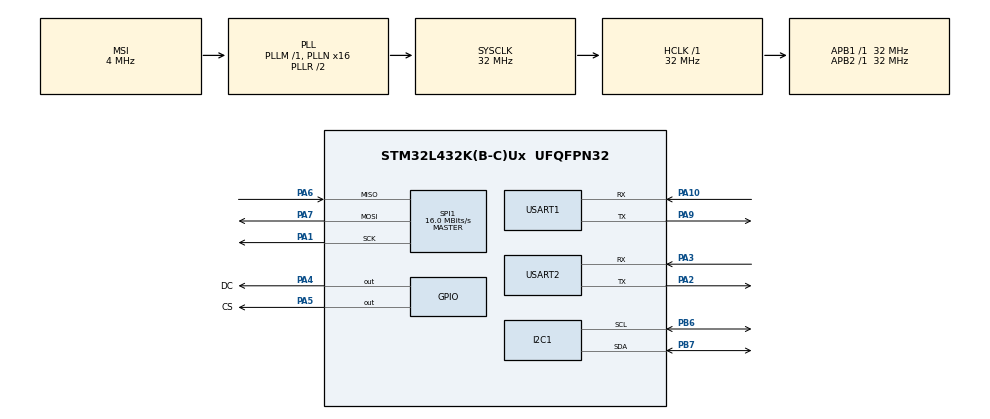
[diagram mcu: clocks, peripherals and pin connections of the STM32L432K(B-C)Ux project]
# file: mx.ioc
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I2C1.Timing=0x00B07CB4
Mcu.Family=STM32L4
Mcu.Name=STM32L432K(B-C)Ux
Mcu.Package=UFQFPN32
NVIC.PriorityGroup=NVIC_PRIORITYGROUP_4
NVIC.TIM2_IRQn=true\:15\:0\:false\:false\:true\:false\:true\:true
NVIC.TimeBase=TIM2_IRQn
NVIC.TimeBaseIP=TIM2
NVIC.USART1_IRQn=true\:5\:0\:true\:false\:true\:true\:true\:true
NVIC.USART2_IRQn=true\:5\:0\:true\:false\:true\:true\:true\:true
PA0.GPIO_Label=MCO [High speed clock in]
PA0.Mode=HSE-External-Clock-Source-for-LittleOrca
PA0.Signal=RCC_CK_IN
PA1.Mode=Full_Duplex_Master
PA1.Signal=SPI1_SCK
PA10.Mode=Asynchronous
PA10.Signal=USART1_RX
PA13\ (JTMS-SWDIO).GPIO_Label=SWDIO
PA13\ (JTMS-SWDIO).Mode=Serial_Wire
PA13\ (JTMS-SWDIO).Signal=SYS_JTMS-SWDIO
PA14\ (JTCK-SWCLK).GPIO_Label=SWCLK
PA14\ (JTCK-SWCLK).Mode=Serial_Wire
PA14\ (JTCK-SWCLK).Signal=SYS_JTCK-SWCLK
PA2.Mode=Asynchronous
PA2.Signal=USART2_TX
PA3.Mode=Asynchronous
PA3.Signal=USART2_RX
PA4.GPIO_Label=DC
PA4.Signal=GPIO_Output
PA5.GPIO_Label=CS
PA5.Signal=GPIO_Output
PA6.Mode=Full_Duplex_Master
PA6.Signal=SPI1_MISO
PA7.Mode=Full_Duplex_Master
PA7.Signal=SPI1_MOSI
PA9.Mode=Asynchronous
PA9.Signal=USART1_TX
PB6.GPIO_Pu=GPIO_PULLUP
PB6.Mode=I2C
PB6.Signal=I2C1_SCL
PB7.GPIO_Pu=GPIO_PULLUP
PB7.Mode=I2C
PB7.Signal=I2C1_SDA
PC14-OSC32_IN\ (PC14).Mode=LSE-External-Oscillator
PC14-OSC32_IN\ (PC14).Signal=RCC_OSC32_IN
PC15-OSC32_OUT\ (PC15).Mode=LSE-External-Oscillator
PC15-OSC32_OUT\ (PC15).Signal=RCC_OSC32_OUT
ProjectManager.HeapSize=0x200
ProjectManager.StackSize=0x400
ProjectManager.TargetToolchain=Makefile
RCC.AHBFreq_Value=32000000
RCC.APB1Freq_Value=32000000
RCC.APB1TimFreq_Value=32000000
RCC.APB2Freq_Value=32000000
RCC.APB2TimFreq_Value=32000000
RCC.CortexFreq_Value=32000000
RCC.HCLKFreq_Value=32000000
RCC.HSE_VALUE=8000000
RCC.HSI16_VALUE=16000000
RCC.HSI48_VALUE=48000000
RCC.HSI_VALUE=16000000
RCC.MSI_VALUE=4000000
RCC.PLLMUL=RCC_PLLMUL_4
RCC.PLLN=16
RCC.SYSCLKFreq_VALUE=32000000
RCC.SYSCLKSource=RCC_SYSCLKSOURCE_PLLCLK
RCC.VCOOutputFreq_Value=64000000
SPI1.CalculateBaudRate=16.0 MBits/s
SPI1.DataSize=SPI_DATASIZE_8BIT
SPI1.Direction=SPI_DIRECTION_2LINES
SPI1.Mode=SPI_MODE_MASTER
SPI1.VirtualType=VM_MASTER
USART1.VirtualMode-Asynchronous=VM_ASYNC
USART2.VirtualMode-Asynchronous=VM_ASYNC
VP_SYS_VS_tim2.Mode=TIM2
board=NUCLEO-L432KC

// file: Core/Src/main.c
/* USER CODE BEGIN Header */
/**
  ******************************************************************************
  * @file           : main.c
  * @brief          : Main program body
  ******************************************************************************
  * @attention
  *
  * Copyright (c) 2026 STMicroelectronics.
  * All rights reserved.
  *
  * This software is licensed under terms that can be found in the LICENSE file
  * in the root directory of this software component.
  * If no LICENSE file comes with this software, it is provided AS-IS.
  *
  ******************************************************************************
  */
/* USER CODE END Header */
#include "main.h"
#include "i2c.h"
#include "spi.h"
#include "usart.h"
#include "gpio.h"

/* USER CODE BEGIN Includes */
#include "stdio.h"
#include "ili9341.h"

#include "FreeRTOS.h"
#include "queue.h"
#include "task.h"
#include <stdio.h>
#include <stdlib.h>
#include <string.h>
/* USER CODE END Includes */

/* USER CODE BEGIN PD */
#define AMG8833_ADDR (0x69 << 1)
/* USER CODE END PD */

/* USER CODE BEGIN PV */

QueueHandle_t uart_queue;

volatile uint8_t rx_byte;

// states
volatile uint8_t auto_mode = 0;
volatile uint8_t thermal_mode = 0;
volatile uint8_t shoot_enabled = 0;

volatile uint16_t aim_value = 1650;

volatile uint16_t motor1_speed = 600;
volatile uint16_t motor2_speed = 600;

const uint16_t image2[] = {
0x07FF,0x07FF,0x07FF,0x07FF,0x07FF,0x07FF,0x07FF,0x07FF,0x07FF,0x07FF,0x07FF,0x07FF,0x07FF,0x07FF,0x07FF,0x07FF,0x07FF,0x07FF,0x07FF,0x07FF,0x07FF,0x07FF,0x07FF,0x07FF,0x07FF,0x07FF,0x07FF,0x07FF,0x07FF,0x07FF,0x07FF,0x07FF,0x07FF,0x07FF,0x07FF,0x07FF,0x07FF,0x0c,0x00,0x00,0x00,0x00,0x00,0x00,0x00,0x00,0x00,0x00,0x11,0x07FF,0x07FF,0x07FF,0x07FF,0x07FF,0x07FF,0x07FF,0x07FF,0x07FF,0x07FF,0x07FF,0x07FF,0x07FF,0x07FF,0x07FF,0x07FF
,0x07FF,0x07FF,0x07FF,0x07FF,0x07FF,0x07FF,0x07FF,0x07FF,0x07FF,0x07FF,0x07FF,0x07FF,0x07FF,0x07FF,0x07FF,0x07FF,0x07FF,0x07FF,0x07FF,0x07FF,0x07FF,0x07FF,0x07FF,0x07FF,0x07FF,0x07FF,0x07FF,0x07FF,0x0c,0x04,0x04,0x04,0x04,0x08,0x07FF,0x07FF,0x0c,0x04,0x00,0xb4,0x24,0x00,0x00,0x00,0x00,0x00,0x24,0xb4,0x04,0x0c,0x07FF,0x07FF,0x04,0x04,0x0c,0x07FF,0x07FF,0x07FF,0x07FF,0x07FF,0x07FF,0x07FF,0x07FF,0x07FF,0x07FF
,0x07FF,0x07FF,0x07FF,0x07FF,0x07FF,0x07FF,0x07FF,0x07FF,0x07FF,0x07FF,0x07FF,0x07FF,0x07FF,0x07FF,0x07FF,0x07FF,0x07FF,0x07FF,0x07FF,0x07FF,0x07FF,0x07FF,0x07FF,0x07FF,0x07FF,0x07FF,0x07FF,0x07FF,0x0c,0x00,0x6c,0x6c,0x24,0x00,0x0c,0x0c,0x04,0x20,0x6c,0x90,0x24,0x00,0x00,0x00,0x00,0x24,0x90,0xfc,0x00,0x04,0x0c,0x0c,0x00,0x00,0x08,0x07FF,0x07FF,0x07FF,0x07FF,0x07FF,0x07FF,0x07FF,0x07FF,0x07FF,0x07FF
,0x07FF,0x07FF,0x07FF,0x07FF,0x07FF,0x07FF,0x07FF,0x07FF,0x07FF,0x07FF,0x07FF,0x07FF,0x07FF,0x07FF,0x07FF,0x07FF,0x07FF,0x07FF,0x07FF,0x07FF,0x07FF,0x07FF,0x07FF,0x07FF,0x07FF,0x07FF,0x07FF,0x07FF,0x0c,0x00,0xd8,0xfc,0x90,0x24,0x24,0x24,0x00,0x44,0xd8,0x24,0x24,0x24,0x24,0x24,0x24,0x6c,0xd8,0xd8,0x24,0x00,0x00,0x00,0x24,0x00,0x08,0x07FF,0x07FF,0x07FF,0x07FF,0x07FF,0x07FF,0x07FF,0x07FF,0x07FF,0x07FF
,0x07FF,0x07FF,0x07FF,0x07FF,0x07FF,0x07FF,0x07FF,0x07FF,0x07FF,0x07FF,0x07FF,0x07FF,0x07FF,0x07FF,0x07FF,0x07FF,0x07FF,0x07FF,0x07FF,0x07FF,0x07FF,0x07FF,0x07FF,0x07FF,0x07FF,0x07FF,0x07FF,0x07FF,0x0c,0x00,0x00,0xd8,0xfc,0xfc,0xfc,0xfc,0x6c,0x00,0x00,0xff,0xff,0xff,0xff,0xff,0xff,0x6d,0x00,0x00,0xf8,0x6c,0x00,0x00,0xfc,0x48,0x08,0x07FF,0x07FF,0x07FF,0x07FF,0x07FF,0x07FF,0x07FF,0x07FF,0x07FF,0x07FF
,0x07FF,0x07FF,0x07FF,0x07FF,0x07FF,0x07FF,0x07FF,0x07FF,0x07FF,0x07FF,0x07FF,0x07FF,0x07FF,0x07FF,0x07FF,0x07FF,0x07FF,0x07FF,0x07FF,0x07FF,0x07FF,0x07FF,0x07FF,0x07FF,0x07FF,0x07FF,0x07FF,0x07FF,0x07FF,0x10,0x00,0x00,0x90,0xfc,0xfc,0x24,0x92,0xdb,0xdb,0xff,0xff,0xff,0xff,0xff,0xff,0xff,0xdb,0xdb,0x24,0x90,0xd8,0xd8,0x24,0x00,0x08,0x07FF,0x07FF,0x07FF,0x07FF,0x07FF,0x07FF,0x07FF,0x07FF,0x07FF,0x07FF
,0x07FF,0x07FF,0x07FF,0x07FF,0x07FF,0x07FF,0x07FF,0x07FF,0x07FF,0x07FF,0x07FF,0x07FF,0x07FF,0x07FF,0x07FF,0x07FF,0x07FF,0x07FF,0x07FF,0x07FF,0x07FF,0x07FF,0x07FF,0x07FF,0x07FF,0x07FF,0x07FF,0x07FF,0x07FF,0x07FF,0x0c,0x00,0x24,0x6c,0x6c,0x92,0xdb,0xff,0xff,0x6d,0x6d,0xb6,0xff,0xff,0x92,0x6d,0x92,0xff,0x92,0x6c,0x90,0xfc,0x00,0x08,0x10,0x07FF,0x07FF,0x07FF,0x07FF,0x07FF,0x07FF,0x07FF,0x07FF,0x07FF,0x07FF
,0x07FF,0x07FF,0x07FF,0x07FF,0x07FF,0x07FF,0x07FF,0x07FF,0x07FF,0x07FF,0x07FF,0x07FF,0x07FF,0x07FF,0x07FF,0x07FF,0x07FF,0x07FF,0x07FF,0x07FF,0x07FF,0x07FF,0x07FF,0x07FF,0x07FF,0x07FF,0x07FF,0x07FF,0x07FF,0x07FF,0x07FF,0x08,0x00,0x00,0x00,0xff,0xff,0xff,0xff,0x00,0x00,0x6d,0xff,0xff,0x24,0x00,0x24,0xff,0xff,0x6d,0x24,0xb4,0x00,0x0c,0x07FF,0x07FF,0x07FF,0x07FF,0x07FF,0x07FF,0x07FF,0x07FF,0x07FF,0x07FF,0x07FF
,0x07FF,0x07FF,0x07FF,0x07FF,0x07FF,0x07FF,0x07FF,0x07FF,0x07FF,0x07FF,0x07FF,0x07FF,0x07FF,0x07FF,0x07FF,0x07FF,0x07FF,0x07FF,0x07FF,0x07FF,0x07FF,0x07FF,0x07FF,0x07FF,0x07FF,0x07FF,0x07FF,0x07FF,0x07FF,0x07FF,0x07FF,0x07FF,0x08,0x00,0x00,0xff,0xff,0xff,0xff,0x00,0x00,0x6d,0xff,0xff,0x24,0x00,0x24,0xff,0xff,0x6d,0x00,0x00,0x00,0x0c,0x07FF,0x07FF,0x07FF,0x07FF,0x07FF,0x07FF,0x07FF,0x07FF,0x07FF,0x07FF,0x07FF
,0x07FF,0x07FF,0x07FF,0x07FF,0x07FF,0x07FF,0x07FF,0x07FF,0x07FF,0x07FF,0x07FF,0x07FF,0x07FF,0x07FF,0x07FF,0x07FF,0x07FF,0x07FF,0x07FF,0x07FF,0x07FF,0x07FF,0x07FF,0x07FF,0x07FF,0x07FF,0x07FF,0x07FF,0x07FF,0x07FF,0x07FF,0x07FF,0x07FF,0x10,0x00,0xff,0xff,0xff,0xff,0xff,0xff,0xff,0xff,0xff,0xff,0xff,0xff,0xff,0xff,0x6d,0x04,0x07FF,0x07FF,0x07FF,0x07FF,0x07FF,0x07FF,0x07FF,0x07FF,0x07FF,0x07FF,0x07FF,0x07FF,0x07FF,0x07FF
,0x07FF,0x07FF,0x07FF,0x07FF,0x07FF,0x07FF,0x07FF,0x07FF,0x07FF,0x07FF,0x07FF,0x07FF,0x07FF,0x07FF,0x07FF,0x07FF,0x07FF,0x07FF,0x07FF,0x07FF,0x07FF,0x07FF,0x07FF,0x07FF,0x07FF,0x07FF,0x07FF,0x07FF,0x07FF,0x07FF,0x07FF,0x07FF,0x07FF,0x10,0x00,0xff,0xff,0xff,0xff,0xff,0xff,0xff,0xff,0xff,0xff,0xff,0xff,0xff,0xff,0x6d,0x04,0x07FF,0x07FF,0x07FF,0x07FF,0x07FF,0x07FF,0x07FF,0x07FF,0x07FF,0x07FF,0x07FF,0x07FF,0x07FF,0x07FF
,0x07FF,0x07FF,0x07FF,0x07FF,0x07FF,0x07FF,0x07FF,0x07FF,0x07FF,0x07FF,0x07FF,0x07FF,0x07FF,0x07FF,0x07FF,0x07FF,0x07FF,0x07FF,0x07FF,0x07FF,0x07FF,0x07FF,0x07FF,0x07FF,0x07FF,0x07FF,0x07FF,0x07FF,0x07FF,0x07FF,0x07FF,0x07FF,0x07FF,0x10,0x00,0xff,0xff,0xdb,0x92,0xff,0xff,0xff,0xff,0xff,0xff,0xdb,0xb6,0xff,0xff,0x6d,0x04,0x07FF,0x07FF,0x07FF,0x07FF,0x07FF,0x07FF,0x07FF,0x07FF,0x07FF,0x07FF,0x07FF,0x07FF,0x07FF,0x07FF
,0x07FF,0x07FF,0x07FF,0x07FF,0x07FF,0x07FF,0x07FF,0x07FF,0x07FF,0x07FF,0x07FF,0x07FF,0x07FF,0x07FF,0x07FF,0x07FF,0x07FF,0x07FF,0x07FF,0x07FF,0x07FF,0x07FF,0x07FF,0x07FF,0x07FF,0x07FF,0x07FF,0x07FF,0x07FF,0x07FF,0x07FF,0x07FF,0x07FF,0x10,0x00,0xff,0xff,0xb6,0x24,0xdb,0xff,0xff,0xff,0xff,0xff,0x6d,0x49,0xff,0xff,0x6d,0x04,0x07FF,0x07FF,0x07FF,0x07FF,0x07FF,0x07FF,0x07FF,0x07FF,0x07FF,0x07FF,0x07FF,0x07FF,0x07FF,0x07FF
,0x07FF,0x07FF,0x07FF,0x07FF,0x07FF,0x07FF,0x07FF,0x07FF,0x07FF,0x07FF,0x07FF,0x07FF,0x07FF,0x07FF,0x07FF,0x07FF,0x07FF,0x07FF,0x07FF,0x07FF,0x07FF,0x07FF,0x07FF,0x07FF,0x07FF,0x07FF,0x07FF,0x07FF,0x07FF,0x07FF,0x07FF,0x07FF,0x07FF,0x10,0x00,0xff,0xff,0xff,0xff,0x00,0xb6,0xff,0xff,0xff,0x24,0x6d,0xff,0xff,0xff,0x6d,0x04,0x07FF,0x07FF,0x07FF,0x07FF,0x07FF,0x07FF,0x07FF,0x07FF,0x07FF,0x07FF,0x07FF,0x07FF,0x07FF,0x07FF
,0x07FF,0x07FF,0x07FF,0x07FF,0x07FF,0x07FF,0x07FF,0x07FF,0x07FF,0x07FF,0x07FF,0x07FF,0x07FF,0x07FF,0x07FF,0x07FF,0x07FF,0x07FF,0x07FF,0x07FF,0x07FF,0x07FF,0x07FF,0x07FF,0x07FF,0x07FF,0x07FF,0x07FF,0x07FF,0x07FF,0x07FF,0x07FF,0x07FF,0x07FF,0x11,0x24,0xb6,0xff,0xff,0xdb,0x49,0x24,0x24,0x24,0xb6,0xff,0xff,0xff,0x24,0x2c,0x11,0x07FF,0x07FF,0x07FF,0x07FF,0x07FF,0x07FF,0x07FF,0x07FF,0x07FF,0x07FF,0x07FF,0x07FF,0x07FF,0x07FF
,0x07FF,0x07FF,0x07FF,0x07FF,0x07FF,0x07FF,0x07FF,0x07FF,0x07FF,0x07FF,0x07FF,0x07FF,0x07FF,0x07FF,0x07FF,0x07FF,0x07FF,0x07FF,0x07FF,0x07FF,0x07FF,0x07FF,0x07FF,0x07FF,0x07FF,0x07FF,0x07FF,0x07FF,0x07FF,0x07FF,0x07FF,0x07FF,0x07FF,0x07FF,0x07FF,0x0c,0x4d,0x6d,0x6d,0xff,0xb6,0x92,0x92,0x92,0xff,0xb6,0x6d,0x6d,0x0c,0x10,0x07FF,0x07FF,0x07FF,0x07FF,0x07FF,0x07FF,0x07FF,0x07FF,0x07FF,0x07FF,0x07FF,0x07FF,0x07FF,0x07FF,0x07FF
,0x07FF,0x07FF,0x07FF,0x07FF,0x07FF,0x07FF,0x07FF,0x07FF,0x07FF,0x07FF,0x07FF,0x07FF,0x07FF,0x07FF,0x07FF,0x07FF,0x07FF,0x07FF,0x07FF,0x07FF,0x07FF,0x07FF,0x07FF,0x07FF,0x07FF,0x07FF,0x07FF,0x07FF,0x07FF,0x07FF,0x07FF,0x07FF,0x07FF,0x07FF,0x07FF,0x07FF,0x0c,0x04,0x04,0xb6,0xb6,0xb6,0xb6,0xb6,0xb6,0x4d,0x04,0x04,0x15,0x07FF,0x07FF,0x07FF,0x07FF,0x07FF,0x07FF,0x07FF,0x07FF,0x07FF,0x07FF,0x07FF,0x07FF,0x07FF,0x07FF,0x07FF,0x07FF
,0x07FF,0x07FF,0x07FF,0x07FF,0x07FF,0x07FF,0x07FF,0x07FF,0x07FF,0x07FF,0x07FF,0x07FF,0x07FF,0x07FF,0x07FF,0x07FF,0x07FF,0x07FF,0x07FF,0x07FF,0x07FF,0x07FF,0x07FF,0x07FF,0x07FF,0x07FF,0x07FF,0x07FF,0x07FF,0x07FF,0x07FF,0x07FF,0x07FF,0x07FF,0x07FF,0x07FF,0x07FF,0x07FF,0x07FF,0x00,0x00,0x00,0x00,0x00,0x00,0x08,0x07FF,0x07FF,0x07FF,0x07FF,0x07FF,0x07FF,0x07FF,0x07FF,0x07FF,0x07FF,0x07FF,0x07FF,0x07FF,0x07FF,0x07FF,0x07FF,0x07FF,0x07FF,0x07FF
,0x07FF,0x07FF,0x07FF,0x07FF,0x07FF,0x07FF,0x07FF,0x07FF,0x07FF,0x07FF,0x07FF,0x07FF,0x07FF,0x07FF,0x07FF,0x07FF,0x07FF,0x07FF,0x07FF,0x07FF,0x07FF,0x07FF,0x07FF,0x07FF,0x07FF,0x07FF,0x07FF,0x07FF,0x07FF,0x07FF,0x07FF,0x07FF,0x07FF,0x07FF,0x07FF,0x07FF,0x07FF,0x07FF,0x07FF,0x00,0x45,0x60,0x60,0x60,0x00,0x08,0x07FF,0x07FF,0x07FF,0x07FF,0x07FF,0x07FF,0x07FF,0x07FF,0x07FF,0x07FF,0x07FF,0x07FF,0x07FF,0x07FF,0x07FF,0x07FF,0x07FF,0x07FF,0x07FF
,0x07FF,0x07FF,0x07FF,0x07FF,0x07FF,0x07FF,0x07FF,0x07FF,0x07FF,0x07FF,0x07FF,0x07FF,0x07FF,0x07FF,0x07FF,0x07FF,0x07FF,0x07FF,0x07FF,0x07FF,0x07FF,0x07FF,0x07FF,0x07FF,0x07FF,0x07FF,0x07FF,0x07FF,0x07FF,0x07FF,0x07FF,0x07FF,0x07FF,0x07FF,0x07FF,0x07FF,0x07FF,0x07FF,0x07FF,0x00,0x45,0x60,0x60,0x60,0x00,0x08,0x07FF,0x07FF,0x07FF,0x07FF,0x07FF,0x07FF,0x07FF,0x07FF,0x07FF,0x07FF,0x07FF,0x07FF,0x07FF,0x07FF,0x07FF,0x07FF,0x07FF,0x07FF,0x07FF
,0x07FF,0x07FF,0x07FF,0x07FF,0x07FF,0x07FF,0x07FF,0x07FF,0x07FF,0x07FF,0x07FF,0x07FF,0x07FF,0x07FF,0x07FF,0x07FF,0x07FF,0x07FF,0x07FF,0x07FF,0x07FF,0x07FF,0x07FF,0x07FF,0x07FF,0x07FF,0x07FF,0x07FF,0x07FF,0x07FF,0x07FF,0x07FF,0x07FF,0x07FF,0x07FF,0x07FF,0x07FF,0x07FF,0x07FF,0x00,0x45,0x60,0x60,0x60,0x00,0x08,0x07FF,0x07FF,0x07FF,0x07FF,0x07FF,0x07FF,0x07FF,0x07FF,0x07FF,0x07FF,0x07FF,0x07FF,0x07FF,0x07FF,0x07FF,0x07FF,0x07FF,0x07FF,0x07FF
,0x07FF,0x07FF,0x07FF,0x07FF,0x07FF,0x07FF,0x07FF,0x07FF,0x07FF,0x07FF,0x07FF,0x07FF,0x07FF,0x07FF,0x07FF,0x07FF,0x07FF,0x07FF,0x07FF,0x07FF,0x07FF,0x07FF,0x07FF,0x07FF,0x07FF,0x07FF,0x07FF,0x07FF,0x07FF,0x11,0x11,0x11,0x11,0x11,0x11,0x11,0x11,0x11,0x11,0x00,0x45,0x60,0x60,0x60,0x00,0x08,0x11,0x11,0x11,0x11,0x11,0x11,0x11,0x11,0x11,0x11,0x07FF,0x07FF,0x07FF,0x07FF,0x07FF,0x07FF,0x07FF,0x07FF,0x07FF
,0x07FF,0x07FF,0x07FF,0x07FF,0x07FF,0x07FF,0x07FF,0x07FF,0x07FF,0x07FF,0x07FF,0x07FF,0x07FF,0x07FF,0x07FF,0x07FF,0x07FF,0x07FF,0x07FF,0x07FF,0x07FF,0x07FF,0x07FF,0x07FF,0x07FF,0x07FF,0x07FF,0x07FF,0x0c,0x00,0x00,0x00,0x00,0x00,0x00,0x00,0x00,0x00,0x00,0x00,0x45,0x60,0x60,0x60,0x00,0x00,0x00,0x00,0x00,0x00,0x00,0x00,0x00,0x00,0x00,0x00,0x07FF,0x07FF,0x07FF,0x07FF,0x07FF,0x07FF,0x07FF,0x07FF,0x07FF
,0x07FF,0x07FF,0x07FF,0x07FF,0x07FF,0x07FF,0x07FF,0x07FF,0x07FF,0x07FF,0x07FF,0x07FF,0x07FF,0x07FF,0x07FF,0x07FF,0x07FF,0x07FF,0x07FF,0x07FF,0x07FF,0x07FF,0x07FF,0x07FF,0x07FF,0x07FF,0x07FF,0x08,0x20,0x46,0x46,0x46,0x46,0x46,0x46,0x46,0x46,0x46,0x46,0x46,0x60,0x60,0x60,0x60,0x60,0x46,0x46,0x46,0x46,0x46,0x46,0x46,0x46,0x46,0x46,0x45,0x00,0x10,0x07FF,0x07FF,0x07FF,0x07FF,0x07FF,0x07FF,0x07FF
,0x07FF,0x07FF,0x07FF,0x07FF,0x07FF,0x07FF,0x07FF,0x07FF,0x07FF,0x07FF,0x07FF,0x07FF,0x07FF,0x07FF,0x07FF,0x07FF,0x07FF,0x07FF,0x07FF,0x07FF,0x07FF,0x07FF,0x07FF,0x07FF,0x07FF,0x07FF,0x08,0x25,0x45,0x60,0x60,0x60,0x60,0x60,0x60,0x60,0x60,0x60,0x60,0x60,0x60,0x60,0x60,0x60,0x60,0x60,0x60,0x60,0x60,0x60,0x60,0x60,0x60,0x60,0x60,0x60,0x21,0x08,0x0c,0x07FF,0x07FF,0x07FF,0x07FF,0x07FF,0x07FF
,0x07FF,0x07FF,0x07FF,0x07FF,0x07FF,0x07FF,0x07FF,0x07FF,0x07FF,0x07FF,0x07FF,0x07FF,0x07FF,0x07FF,0x07FF,0x07FF,0x07FF,0x07FF,0x07FF,0x07FF,0x07FF,0x07FF,0x07FF,0x07FF,0x15,0x0c,0x00,0x45,0x60,0x60,0x60,0x60,0x60,0x60,0x60,0x60,0x60,0x60,0x60,0x60,0x60,0x60,0x60,0x60,0x60,0x60,0x60,0x60,0x60,0x60,0x60,0x60,0x60,0x60,0x60,0x60,0x60,0x21,0x08,0x10,0x07FF,0x07FF,0x07FF,0x07FF,0x07FF
,0x07FF,0x07FF,0x07FF,0x07FF,0x07FF,0x07FF,0x07FF,0x07FF,0x07FF,0x07FF,0x07FF,0x07FF,0x07FF,0x07FF,0x07FF,0x07FF,0x07FF,0x07FF,0x07FF,0x07FF,0x07FF,0x07FF,0x07FF,0x07FF,0x0c,0x00,0x60,0x60,0x60,0x60,0x60,0x60,0x60,0x60,0x60,0x60,0x60,0x60,0x60,0x60,0x60,0x60,0x60,0x60,0x60,0x60,0x60,0x60,0x60,0x60,0x60,0x60,0x60,0x60,0x60,0x60,0x60,0x60,0x21,0x04,0x07FF,0x07FF,0x07FF,0x07FF,0x07FF
,0x07FF,0x07FF,0x07FF,0x07FF,0x07FF,0x07FF,0x07FF,0x07FF,0x07FF,0x07FF,0x07FF,0x07FF,0x07FF,0x07FF,0x07FF,0x07FF,0x07FF,0x07FF,0x07FF,0x07FF,0x07FF,0x07FF,0x07FF,0x08,0x20,0x60,0x60,0x60,0x60,0x60,0x60,0x60,0x60,0x60,0x60,0x60,0x60,0x60,0x60,0x60,0x60,0x60,0x60,0x60,0x60,0x60,0x60,0x60,0x60,0x60,0x60,0x60,0x60,0x60,0x60,0x60,0x60,0x60,0x60,0x45,0x00,0x11,0x07FF,0x07FF,0x07FF
,0x07FF,0x07FF,0x07FF,0x07FF,0x07FF,0x07FF,0x07FF,0x07FF,0x07FF,0x07FF,0x07FF,0x07FF,0x07FF,0x07FF,0x07FF,0x07FF,0x07FF,0x07FF,0x07FF,0x07FF,0x07FF,0x07FF,0x04,0x25,0x45,0x60,0x60,0x60,0x60,0x60,0x60,0x60,0x60,0x60,0x60,0x60,0x60,0x60,0x60,0x60,0x60,0x60,0x60,0x60,0x60,0x60,0x60,0x60,0x60,0x60,0x60,0x60,0x60,0x60,0x60,0x60,0x60,0x60,0x60,0x45,0x00,0x11,0x07FF,0x07FF,0x07FF
,0x07FF,0x07FF,0x07FF,0x07FF,0x07FF,0x07FF,0x07FF,0x07FF,0x07FF,0x07FF,0x07FF,0x07FF,0x07FF,0x07FF,0x07FF,0x07FF,0x07FF,0x07FF,0x07FF,0x07FF,0x07FF,0x07FF,0x00,0x20,0x45,0x60,0x60,0x60,0x60,0x60,0x60,0x45,0x21,0x45,0x60,0x60,0x60,0x60,0x60,0x60,0x60,0x60,0x60,0x60,0x60,0x60,0x60,0x60,0x60,0x60,0x60,0x21,0x21,0x60,0x60,0x60,0x60,0x60,0x60,0x45,0x00,0x11,0x07FF,0x07FF,0x07FF
,0x07FF,0x07FF,0x07FF,0x07FF,0x07FF,0x07FF,0x07FF,0x07FF,0x07FF,0x07FF,0x07FF,0x07FF,0x07FF,0x07FF,0x07FF,0x07FF,0x07FF,0x07FF,0x07FF,0x07FF,0x07FF,0x11,0x00,0x00,0x25,0x46,0x60,0x60,0x60,0x60,0x46,0x00,0x00,0x00,0x60,0x60,0x60,0x60,0x60,0x60,0x60,0x60,0x60,0x60,0x60,0x60,0x60,0x60,0x60,0x60,0x45,0x00,0x00,0x45,0x60,0x60,0x60,0x60,0x60,0x45,0x00,0x11,0x07FF,0x07FF,0x07FF
,0x07FF,0x07FF,0x07FF,0x07FF,0x07FF,0x07FF,0x07FF,0x07FF,0x07FF,0x07FF,0x07FF,0x07FF,0x07FF,0x07FF,0x07FF,0x07FF,0x07FF,0x07FF,0x07FF,0x07FF,0x10,0x00,0x00,0x92,0xb6,0x00,0x60,0x60,0x60,0x60,0x00,0x10,0x08,0x00,0x60,0x60,0x60,0x60,0x60,0x60,0x60,0x60,0x60,0x60,0x60,0x60,0x60,0x60,0x60,0x60,0x45,0x00,0x00,0x45,0x60,0x60,0x60,0x60,0x60,0x45,0x00,0x11,0x07FF,0x07FF,0x07FF
,0x07FF,0x07FF,0x07FF,0x07FF,0x07FF,0x07FF,0x07FF,0x07FF,0x07FF,0x07FF,0x07FF,0x07FF,0x07FF,0x07FF,0x07FF,0x07FF,0x07FF,0x07FF,0x07FF,0x0c,0x00,0x00,0xdb,0xff,0xff,0xdb,0x00,0x45,0x45,0x00,0x11,0x07FF,0x08,0x00,0x60,0x60,0x60,0x60,0x60,0x60,0x60,0x60,0x60,0x60,0x60,0x60,0x60,0x60,0x60,0x60,0x45,0x00,0x00,0x45,0x60,0x60,0x60,0x60,0x60,0x45,0x00,0x11,0x07FF,0x07FF,0x07FF
,0x07FF,0x07FF,0x07FF,0x07FF,0x07FF,0x07FF,0x07FF,0x07FF,0x07FF,0x07FF,0x07FF,0x07FF,0x07FF,0x07FF,0x07FF,0x07FF,0x07FF,0x07FF,0x0c,0x04,0x00,0x92,0xff,0xff,0xff,0xff,0x00,0x20,0x24,0x0c,0x07FF,0x07FF,0x08,0x00,0x60,0x60,0x60,0x60,0x60,0x60,0x60,0x60,0x60,0x60,0x60,0x60,0x60,0x60,0x60,0x60,0x45,0x00,0x00,0x45,0x60,0x60,0x60,0x60,0x60,0x45,0x00,0x11,0x07FF,0x07FF,0x07FF
,0x07FF,0x07FF,0x07FF,0x07FF,0x07FF,0x07FF,0x07FF,0x07FF,0x07FF,0x07FF,0x07FF,0x07FF,0x07FF,0x07FF,0x07FF,0x07FF,0x07FF,0x0c,0x00,0x24,0x6d,0xff,0xff,0xff,0xff,0xb6,0x00,0x04,0x0c,0x07FF,0x07FF,0x07FF,0x08,0x00,0x60,0x60,0x60,0x60,0x60,0x60,0x60,0x60,0x60,0x60,0x60,0x60,0x60,0x60,0x60,0x60,0x45,0x00,0x00,0x45,0x60,0x60,0x60,0x60,0x60,0x45,0x00,0x11,0x07FF,0x07FF,0x07FF
,0x07FF,0x07FF,0x07FF,0x07FF,0x07FF,0x07FF,0x07FF,0x07FF,0x07FF,0x07FF,0x07FF,0x07FF,0x07FF,0x07FF,0x07FF,0x07FF,0x11,0x00,0x00,0x6d,0xff,0xff,0xff,0xff,0xb6,0x00,0x00,0x0c,0x07FF,0x07FF,0x07FF,0x07FF,0x08,0x00,0x60,0x60,0x60,0x60,0x60,0x60,0x60,0x60,0x60,0x60,0x60,0x60,0x60,0x60,0x60,0x60,0x45,0x00,0x00,0x45,0x60,0x60,0x60,0x60,0x60,0x45,0x00,0x11,0x07FF,0x07FF,0x07FF
,0x07FF,0x07FF,0x07FF,0x11,0x00,0x00,0x00,0x00,0x00,0x11,0x07FF,0x07FF,0x07FF,0x07FF,0x07FF,0x0c,0x00,0x00,0xdb,0xff,0xff,0xff,0xff,0x6d,0x00,0x00,0x07FF,0x07FF,0x07FF,0x07FF,0x07FF,0x07FF,0x08,0x00,0x60,0x60,0x60,0x60,0x60,0x60,0x60,0x60,0x60,0x60,0x60,0x60,0x60,0x60,0x60,0x60,0x45,0x00,0x00,0x45,0x60,0x60,0x60,0x60,0x60,0x45,0x00,0x11,0x07FF,0x07FF,0x07FF
,0x07FF,0x07FF,0x0c,0x04,0xa0,0xa0,0xa0,0xa0,0xa0,0x04,0x0c,0x07FF,0x07FF,0x07FF,0x08,0x00,0x00,0x00,0xdb,0xff,0xff,0xff,0x49,0x00,0x04,0x0c,0x07FF,0x07FF,0x07FF,0x07FF,0x07FF,0x07FF,0x08,0x00,0x60,0x60,0x60,0x60,0x60,0x60,0x60,0x60,0x60,0x60,0x60,0x60,0x60,0x60,0x60,0x60,0x45,0x00,0x00,0x00,0x00,0x00,0x00,0x00,0x00,0x00,0x00,0x11,0x07FF,0x07FF,0x07FF
,0x07FF,0x0c,0x28,0x60,0xe0,0xe0,0xe0,0xe0,0xe0,0x60,0x28,0x0c,0x07FF,0x07FF,0x04,0x00,0x00,0x6d,0xff,0xff,0xff,0x92,0x00,0x04,0x0c,0x07FF,0x07FF,0x07FF,0x07FF,0x07FF,0x07FF,0x07FF,0x08,0x00,0x60,0x60,0x60,0x60,0x60,0x60,0x60,0x60,0x60,0x60,0x60,0x60,0x60,0x60,0x60,0x60,0x45,0x00,0x08,0x08,0x04,0x00,0x6d,0x6d,0x24,0x00,0x08,0x07FF,0x07FF,0x07FF,0x07FF
,0x07FF,0x04,0x40,0xe0,0xe0,0xe0,0xe0,0xe0,0xe0,0xe0,0x40,0x04,0x07FF,0x11,0x04,0x00,0x24,0xff,0xff,0xff,0xb6,0x00,0x00,0x0c,0x07FF,0x07FF,0x07FF,0x07FF,0x07FF,0x07FF,0x07FF,0x07FF,0x08,0x00,0x60,0x60,0x60,0x60,0x60,0x60,0x60,0x60,0x60,0x60,0x60,0x60,0x60,0x60,0x60,0x60,0x45,0x00,0x07FF,0x07FF,0x0c,0x00,0xff,0xff,0x6d,0x04,0x07FF,0x07FF,0x07FF,0x07FF,0x07FF
,0x07FF,0x04,0x40,0xe0,0xe0,0xe0,0xe0,0xe0,0xe0,0xe0,0x40,0x04,0x07FF,0x00,0x00,0x6d,0xff,0xff,0xff,0x6d,0x00,0x00,0x11,0x07FF,0x07FF,0x07FF,0x07FF,0x07FF,0x07FF,0x07FF,0x07FF,0x07FF,0x08,0x00,0x60,0x60,0x60,0x60,0x60,0x60,0x60,0x60,0x60,0x60,0x60,0x60,0x60,0x60,0x60,0x60,0x45,0x00,0x07FF,0x07FF,0x0c,0x00,0xff,0xff,0x6d,0x04,0x07FF,0x07FF,0x07FF,0x07FF,0x07FF
,0x07FF,0x04,0x40,0xe0,0xe0,0xe0,0xe0,0xe0,0xe0,0xe0,0x40,0x00,0x00,0x00,0x92,0xff,0xff,0xff,0x49,0x00,0x00,0x11,0x07FF,0x07FF,0x07FF,0x07FF,0x07FF,0x07FF,0x07FF,0x07FF,0x07FF,0x07FF,0x08,0x00,0x60,0x60,0x60,0x60,0x60,0x60,0x60,0x60,0x60,0x60,0x60,0x60,0x60,0x60,0x60,0x60,0x45,0x00,0x07FF,0x07FF,0x0c,0x00,0xff,0xff,0x6d,0x04,0x07FF,0x07FF,0x07FF,0x07FF,0x07FF
,0x07FF,0x04,0x40,0xe0,0xe0,0xe0,0xe0,0xe0,0xe0,0xe0,0x40,0x00,0x00,0x92,0xdb,0xff,0xff,0x6d,0x00,0x04,0x0c,0x07FF,0x07FF,0x07FF,0x07FF,0x07FF,0x07FF,0x07FF,0x07FF,0x07FF,0x07FF,0x07FF,0x08,0x00,0x60,0x60,0x60,0x60,0x60,0x60,0x60,0x60,0x60,0x60,0x60,0x60,0x60,0x60,0x60,0x60,0x45,0x00,0x07FF,0x07FF,0x0c,0x00,0xff,0xff,0x6d,0x04,0x07FF,0x07FF,0x07FF,0x07FF,0x07FF
,0x07FF,0x08,0x44,0xa0,0xe0,0xe0,0xe0,0xe0,0xe0,0xa0,0x40,0x00,0x00,0xff,0xff,0xff,0xb6,0x00,0x04,0x0c,0x07FF,0x07FF,0x07FF,0x07FF,0x07FF,0x07FF,0x07FF,0x07FF,0x07FF,0x07FF,0x07FF,0x07FF,0x08,0x00,0x60,0x60,0x60,0x60,0x60,0x60,0x60,0x60,0x60,0x60,0x60,0x60,0x60,0x60,0x60,0x60,0x45,0x00,0x07FF,0x07FF,0x0c,0x00,0xff,0xff,0x6d,0x04,0x07FF,0x07FF,0x07FF,0x07FF,0x07FF
,0x07FF,0x07FF,0x0c,0x00,0xe0,0xe0,0xe0,0xe0,0xe0,0x00,0x00,0x00,0x00,0xff,0xff,0x92,0x00,0x00,0x10,0x07FF,0x07FF,0x07FF,0x07FF,0x07FF,0x07FF,0x07FF,0x07FF,0x07FF,0x07FF,0x07FF,0x07FF,0x07FF,0x08,0x00,0x60,0x60,0x60,0x60,0x60,0x60,0x60,0x60,0x60,0x60,0x60,0x60,0x60,0x60,0x60,0x60,0x45,0x00,0x07FF,0x07FF,0x0c,0x00,0xff,0xff,0x6d,0x04,0x07FF,0x07FF,0x07FF,0x07FF,0x07FF
,0x07FF,0x07FF,0x07FF,0x11,0x00,0x00,0x00,0x00,0x00,0x00,0x00,0x00,0x00,0xff,0x49,0x00,0x00,0x07FF,0x07FF,0x07FF,0x07FF,0x07FF,0x07FF,0x07FF,0x07FF,0x07FF,0x07FF,0x07FF,0x07FF,0x07FF,0x07FF,0x07FF,0x08,0x00,0x60,0x60,0x60,0x60,0x60,0x60,0x60,0x60,0x60,0x60,0x60,0x60,0x60,0x60,0x60,0x60,0x45,0x00,0x07FF,0x07FF,0x0c,0x00,0xff,0xff,0x6d,0x04,0x07FF,0x07FF,0x07FF,0x07FF,0x07FF
,0x07FF,0x07FF,0x07FF,0x07FF,0x0c,0x0c,0x0c,0x0c,0x0c,0x0c,0x04,0x00,0x00,0x49,0x00,0x04,0x10,0x07FF,0x07FF,0x07FF,0x07FF,0x07FF,0x07FF,0x07FF,0x07FF,0x07FF,0x07FF,0x07FF,0x07FF,0x07FF,0x07FF,0x07FF,0x08,0x00,0x60,0x60,0x60,0x60,0x60,0x60,0x60,0x60,0x60,0x60,0x60,0x60,0x60,0x60,0x60,0x60,0x45,0x00,0x07FF,0x07FF,0x0c,0x00,0xff,0xff,0x6d,0x04,0x07FF,0x07FF,0x07FF,0x07FF,0x07FF
,0x07FF,0x07FF,0x07FF,0x07FF,0x07FF,0x07FF,0x07FF,0x07FF,0x07FF,0x07FF,0x0c,0x04,0x00,0x00,0x04,0x0c,0x07FF,0x07FF,0x07FF,0x07FF,0x07FF,0x07FF,0x07FF,0x07FF,0x07FF,0x07FF,0x07FF,0x07FF,0x07FF,0x07FF,0x07FF,0x07FF,0x08,0x00,0x60,0x60,0x60,0x60,0x60,0x60,0x60,0x60,0x60,0x60,0x60,0x60,0x60,0x60,0x60,0x60,0x45,0x00,0x07FF,0x07FF,0x0c,0x00,0xff,0xff,0x6d,0x04,0x07FF,0x07FF,0x07FF,0x07FF,0x07FF
,0x07FF,0x07FF,0x07FF,0x07FF,0x07FF,0x07FF,0x07FF,0x07FF,0x07FF,0x07FF,0x07FF,0x10,0x00,0x00,0x10,0x07FF,0x07FF,0x07FF,0x07FF,0x07FF,0x07FF,0x07FF,0x07FF,0x07FF,0x07FF,0x07FF,0x07FF,0x07FF,0x07FF,0x07FF,0x07FF,0x07FF,0x08,0x00,0x60,0x60,0x60,0x60,0x60,0x60,0x60,0x60,0x60,0x60,0x60,0x60,0x60,0x60,0x60,0x60,0x45,0x00,0x07FF,0x11,0x08,0x00,0xff,0xff,0x6d,0x04,0x07FF,0x07FF,0x07FF,0x07FF,0x07FF
,0x07FF,0x07FF,0x07FF,0x07FF,0x07FF,0x07FF,0x07FF,0x07FF,0x07FF,0x07FF,0x07FF,0x07FF,0x07FF,0x07FF,0x07FF,0x07FF,0x07FF,0x07FF,0x07FF,0x07FF,0x07FF,0x07FF,0x07FF,0x07FF,0x07FF,0x07FF,0x07FF,0x07FF,0x07FF,0x07FF,0x07FF,0x07FF,0x08,0x00,0x60,0x60,0x60,0x60,0x60,0x60,0x60,0x60,0x60,0x60,0x60,0x60,0x60,0x60,0x60,0x60,0x45,0x00,0x07FF,0x04,0x00,0x00,0xff,0xff,0x6d,0x04,0x07FF,0x07FF,0x07FF,0x07FF,0x07FF
,0x07FF,0x07FF,0x07FF,0x07FF,0x07FF,0x07FF,0x07FF,0x07FF,0x07FF,0x07FF,0x07FF,0x07FF,0x07FF,0x07FF,0x07FF,0x07FF,0x07FF,0x07FF,0x07FF,0x07FF,0x07FF,0x07FF,0x07FF,0x07FF,0x07FF,0x07FF,0x07FF,0x07FF,0x07FF,0x07FF,0x07FF,0x07FF,0x08,0x00,0x60,0x60,0x60,0x60,0x60,0x60,0x60,0x60,0x60,0x60,0x60,0x60,0x60,0x60,0x60,0x60,0x45,0x00,0x07FF,0x04,0x49,0xdb,0xff,0x49,0x00,0x04,0x07FF,0x07FF,0x07FF,0x07FF,0x07FF
,0x07FF,0x07FF,0x07FF,0x07FF,0x07FF,0x07FF,0x07FF,0x07FF,0x07FF,0x07FF,0x07FF,0x07FF,0x07FF,0x07FF,0x07FF,0x07FF,0x07FF,0x07FF,0x07FF,0x07FF,0x07FF,0x07FF,0x07FF,0x07FF,0x07FF,0x07FF,0x07FF,0x07FF,0x07FF,0x07FF,0x07FF,0x07FF,0x08,0x00,0x60,0x60,0x60,0x60,0x60,0x60,0x60,0x60,0x60,0x60,0x60,0x60,0x60,0x60,0x60,0x60,0x45,0x00,0x08,0x00,0x6d,0xff,0xff,0x24,0x04,0x0c,0x07FF,0x07FF,0x07FF,0x07FF,0x07FF
,0x07FF,0x07FF,0x07FF,0x07FF,0x07FF,0x07FF,0x07FF,0x07FF,0x07FF,0x07FF,0x07FF,0x07FF,0x07FF,0x07FF,0x07FF,0x07FF,0x07FF,0x07FF,0x07FF,0x07FF,0x07FF,0x07FF,0x07FF,0x07FF,0x07FF,0x07FF,0x07FF,0x07FF,0x07FF,0x07FF,0x07FF,0x07FF,0x08,0x00,0x60,0x60,0x60,0x60,0x60,0x60,0x60,0x60,0x60,0x60,0x60,0x60,0x60,0x60,0x60,0x60,0x45,0x00,0x00,0x24,0x92,0xff,0xb6,0x24,0x08,0x07FF,0x07FF,0x07FF,0x07FF,0x07FF,0x07FF
,0x07FF,0x07FF,0x07FF,0x07FF,0x07FF,0x07FF,0x07FF,0x07FF,0x07FF,0x07FF,0x07FF,0x07FF,0x07FF,0x07FF,0x07FF,0x07FF,0x07FF,0x07FF,0x07FF,0x07FF,0x07FF,0x07FF,0x07FF,0x07FF,0x07FF,0x07FF,0x07FF,0x07FF,0x07FF,0x07FF,0x07FF,0x07FF,0x08,0x00,0x60,0x60,0x60,0x60,0x60,0x60,0x60,0x60,0x60,0x60,0x60,0x60,0x60,0x60,0x60,0x60,0x45,0x00,0x00,0xb6,0xff,0xff,0x00,0x00,0x08,0x07FF,0x07FF,0x07FF,0x07FF,0x07FF,0x07FF
,0x07FF,0x07FF,0x07FF,0x07FF,0x07FF,0x07FF,0x07FF,0x07FF,0x07FF,0x07FF,0x07FF,0x07FF,0x07FF,0x07FF,0x07FF,0x07FF,0x07FF,0x07FF,0x07FF,0x07FF,0x07FF,0x07FF,0x07FF,0x07FF,0x07FF,0x07FF,0x07FF,0x07FF,0x07FF,0x07FF,0x07FF,0x07FF,0x08,0x00,0x00,0x00,0x00,0x00,0x00,0x00,0x00,0x00,0x00,0x00,0x00,0x00,0x00,0x00,0x00,0x00,0x00,0x00,0x00,0xb6,0xff,0xff,0x00,0x10,0x07FF,0x07FF,0x07FF,0x07FF,0x07FF,0x07FF,0x07FF
,0x07FF,0x07FF,0x07FF,0x07FF,0x07FF,0x07FF,0x07FF,0x07FF,0x07FF,0x07FF,0x07FF,0x07FF,0x07FF,0x07FF,0x07FF,0x07FF,0x07FF,0x07FF,0x07FF,0x07FF,0x07FF,0x07FF,0x07FF,0x07FF,0x07FF,0x07FF,0x07FF,0x07FF,0x07FF,0x07FF,0x07FF,0x07FF,0x08,0x00,0x00,0x00,0x00,0x00,0x00,0x00,0x00,0x00,0x00,0x00,0x00,0x00,0x00,0x00,0x00,0x00,0x00,0x00,0xb6,0xff,0xb6,0x49,0x0c,0x07FF,0x07FF,0x07FF,0x07FF,0x07FF,0x07FF,0x07FF,0x07FF
,0x07FF,0x07FF,0x07FF,0x07FF,0x07FF,0x07FF,0x07FF,0x07FF,0x07FF,0x07FF,0x07FF,0x07FF,0x07FF,0x07FF,0x07FF,0x07FF,0x07FF,0x07FF,0x07FF,0x07FF,0x07FF,0x07FF,0x07FF,0x07FF,0x07FF,0x07FF,0x07FF,0x07FF,0x07FF,0x07FF,0x07FF,0x07FF,0x08,0x00,0x00,0x00,0x00,0x00,0x00,0x00,0x00,0x00,0x00,0x00,0x00,0x00,0x00,0x00,0x00,0x00,0x00,0x00,0xff,0xb6,0x49,0x00,0x07FF,0x07FF,0x07FF,0x07FF,0x07FF,0x07FF,0x07FF,0x07FF,0x07FF
,0x07FF,0x07FF,0x07FF,0x07FF,0x07FF,0x07FF,0x07FF,0x07FF,0x07FF,0x07FF,0x07FF,0x07FF,0x07FF,0x07FF,0x07FF,0x07FF,0x07FF,0x07FF,0x07FF,0x07FF,0x07FF,0x07FF,0x07FF,0x07FF,0x07FF,0x07FF,0x07FF,0x07FF,0x07FF,0x07FF,0x07FF,0x07FF,0x08,0x00,0x00,0x00,0x00,0x00,0x00,0x00,0x00,0x00,0x00,0x00,0x00,0x00,0x00,0x00,0x00,0x00,0x00,0x00,0xdb,0x49,0x00,0x04,0x07FF,0x07FF,0x07FF,0x07FF,0x07FF,0x07FF,0x07FF,0x07FF,0x07FF
,0x07FF,0x07FF,0x07FF,0x07FF,0x07FF,0x07FF,0x07FF,0x07FF,0x07FF,0x07FF,0x07FF,0x07FF,0x07FF,0x07FF,0x07FF,0x07FF,0x07FF,0x07FF,0x07FF,0x07FF,0x07FF,0x07FF,0x07FF,0x07FF,0x07FF,0x07FF,0x07FF,0x07FF,0x07FF,0x07FF,0x07FF,0x07FF,0x08,0x00,0x00,0x00,0x00,0x00,0x00,0x00,0x00,0x00,0x00,0x00,0x00,0x00,0x00,0x00,0x00,0x00,0x00,0x00,0x00,0x00,0x08,0x07FF,0x07FF,0x07FF,0x07FF,0x07FF,0x07FF,0x07FF,0x07FF,0x07FF,0x07FF
,0x07FF,0x07FF,0x07FF,0x07FF,0x07FF,0x07FF,0x07FF,0x07FF,0x07FF,0x07FF,0x07FF,0x07FF,0x07FF,0x07FF,0x07FF,0x07FF,0x07FF,0x07FF,0x07FF,0x07FF,0x07FF,0x07FF,0x07FF,0x07FF,0x07FF,0x07FF,0x07FF,0x07FF,0x07FF,0x07FF,0x07FF,0x07FF,0x08,0x00,0x00,0x00,0x00,0x00,0x00,0x00,0x00,0x00,0x00,0x00,0x00,0x00,0x00,0x00,0x00,0x00,0x00,0x00,0x11,0x11,0x15,0x07FF,0x07FF,0x07FF,0x07FF,0x07FF,0x07FF,0x07FF,0x07FF,0x07FF,0x07FF
,0x07FF,0x07FF,0x07FF,0x07FF,0x07FF,0x07FF,0x07FF,0x07FF,0x07FF,0x07FF,0x07FF,0x07FF,0x07FF,0x07FF,0x07FF,0x07FF,0x07FF,0x07FF,0x07FF,0x07FF,0x07FF,0x07FF,0x07FF,0x07FF,0x07FF,0x07FF,0x07FF,0x07FF,0x07FF,0x07FF,0x07FF,0x07FF,0x08,0x00,0x00,0x00,0x00,0x00,0x00,0x00,0x00,0x00,0x00,0x00,0x00,0x00,0x00,0x00,0x00,0x00,0x00,0x00,0x07FF,0x07FF,0x07FF,0x07FF,0x07FF,0x07FF,0x07FF,0x07FF,0x07FF,0x07FF,0x07FF,0x07FF,0x07FF
,0x07FF,0x07FF,0x07FF,0x07FF,0x07FF,0x07FF,0x07FF,0x07FF,0x07FF,0x07FF,0x07FF,0x07FF,0x07FF,0x07FF,0x07FF,0x07FF,0x07FF,0x07FF,0x07FF,0x07FF,0x07FF,0x07FF,0x07FF,0x07FF,0x07FF,0x07FF,0x07FF,0x07FF,0x07FF,0x07FF,0x07FF,0x07FF,0x08,0x00,0x00,0x00,0x00,0x00,0x00,0x00,0x00,0x00,0x00,0x00,0x00,0x00,0x00,0x00,0x00,0x00,0x00,0x00,0x07FF,0x07FF,0x07FF,0x07FF,0x07FF,0x07FF,0x07FF,0x07FF,0x07FF,0x07FF,0x07FF,0x07FF,0x07FF
,0x07FF,0x07FF,0x07FF,0x07FF,0x07FF,0x07FF,0x07FF,0x07FF,0x07FF,0x07FF,0x07FF,0x07FF,0x07FF,0x07FF,0x07FF,0x07FF,0x07FF,0x07FF,0x07FF,0x07FF,0x07FF,0x07FF,0x07FF,0x07FF,0x07FF,0x07FF,0x07FF,0x07FF,0x07FF,0x07FF,0x07FF,0x07FF,0x08,0x00,0x00,0x00,0x00,0x00,0x00,0x00,0x00,0x00,0x00,0x00,0x00,0x00,0x00,0x00,0x00,0x00,0x00,0x00,0x07FF,0x07FF,0x07FF,0x07FF,0x07FF,0x07FF,0x07FF,0x07FF,0x07FF,0x07FF,0x07FF,0x07FF,0x07FF
,0x07FF,0x07FF,0x07FF,0x07FF,0x07FF,0x07FF,0x07FF,0x07FF,0x07FF,0x07FF,0x07FF,0x07FF,0x07FF,0x07FF,0x07FF,0x07FF,0x07FF,0x07FF,0x07FF,0x07FF,0x07FF,0x07FF,0x07FF,0x07FF,0x07FF,0x07FF,0x07FF,0x07FF,0x07FF,0x07FF,0x07FF,0x07FF,0x08,0x00,0x00,0x00,0x00,0x00,0x00,0x00,0x00,0x00,0x00,0x00,0x00,0x00,0x00,0x00,0x00,0x00,0x00,0x00,0x07FF,0x07FF,0x07FF,0x07FF,0x07FF,0x07FF,0x07FF,0x07FF,0x07FF,0x07FF,0x07FF,0x07FF,0x07FF
,0x07FF,0x07FF,0x07FF,0x07FF,0x07FF,0x07FF,0x07FF,0x07FF,0x07FF,0x07FF,0x07FF,0x07FF,0x07FF,0x07FF,0x07FF,0x07FF,0x07FF,0x07FF,0x07FF,0x07FF,0x07FF,0x07FF,0x07FF,0x07FF,0x07FF,0x07FF,0x07FF,0x07FF,0x07FF,0x07FF,0x07FF,0x07FF,0x08,0x00,0x00,0x00,0x00,0x00,0x00,0x00,0x00,0x00,0x00,0x00,0x00,0x00,0x00,0x00,0x00,0x00,0x00,0x00,0x07FF,0x07FF,0x07FF,0x07FF,0x07FF,0x07FF,0x07FF,0x07FF,0x07FF,0x07FF,0x07FF,0x07FF,0x07FF
,0x07FF,0x07FF,0x07FF,0x07FF,0x07FF,0x07FF,0x07FF,0x07FF,0x07FF,0x07FF,0x07FF,0x07FF,0x07FF,0x07FF,0x07FF,0x07FF,0x07FF,0x07FF,0x07FF,0x07FF,0x07FF,0x07FF,0x07FF,0x07FF,0x07FF,0x07FF,0x07FF,0x07FF,0x07FF,0x07FF,0x07FF,0x07FF,0x08,0x00,0x00,0x00,0x00,0x00,0x00,0x00,0x00,0x00,0x00,0x00,0x00,0x00,0x00,0x00,0x00,0x00,0x00,0x00,0x07FF,0x07FF,0x07FF,0x07FF,0x07FF,0x07FF,0x07FF,0x07FF,0x07FF,0x07FF,0x07FF,0x07FF,0x07FF
,0x07FF,0x07FF,0x07FF,0x07FF,0x07FF,0x07FF,0x07FF,0x07FF,0x07FF,0x07FF,0x07FF,0x07FF,0x07FF,0x07FF,0x07FF,0x07FF,0x07FF,0x07FF,0x07FF,0x07FF,0x07FF,0x07FF,0x07FF,0x07FF,0x07FF,0x07FF,0x07FF,0x07FF,0x07FF,0x07FF,0x07FF,0x07FF,0x08,0x00,0x00,0x00,0x00,0x00,0x00,0x00,0x00,0x00,0x00,0x00,0x00,0x00,0x00,0x00,0x00,0x00,0x00,0x00,0x07FF,0x07FF,0x07FF,0x07FF,0x07FF,0x07FF,0x07FF,0x07FF,0x07FF,0x07FF,0x07FF,0x07FF,0x07FF
,0x07FF,0x07FF,0x07FF,0x07FF,0x07FF,0x07FF,0x07FF,0x07FF,0x07FF,0x07FF,0x07FF,0x07FF,0x07FF,0x07FF,0x07FF,0x07FF,0x07FF,0x07FF,0x07FF,0x07FF,0x07FF,0x07FF,0x07FF,0x07FF,0x07FF,0x07FF,0x07FF,0x07FF,0x07FF,0x07FF,0x07FF,0x07FF,0x08,0x00,0x00,0x00,0x00,0x00,0x00,0x00,0x00,0x00,0x00,0x00,0x00,0x00,0x00,0x00,0x00,0x00,0x00,0x00,0x07FF,0x07FF,0x07FF,0x07FF,0x07FF,0x07FF,0x07FF,0x07FF,0x07FF,0x07FF,0x07FF,0x07FF,0x07FF
,0x07FF,0x07FF,0x07FF,0x07FF,0x07FF,0x07FF,0x07FF,0x07FF,0x07FF,0x07FF,0x07FF,0x07FF,0x07FF,0x07FF,0x07FF,0x07FF,0x07FF,0x07FF,0x07FF,0x07FF,0x07FF,0x07FF,0x07FF,0x07FF,0x07FF,0x07FF,0x07FF,0x07FF,0x07FF,0x07FF,0x07FF,0x07FF,0x08,0x00,0x00,0x00,0x00,0x00,0x00,0x00,0x00,0x00,0x00,0x00,0x00,0x00,0x00,0x00,0x00,0x00,0x00,0x00,0x07FF,0x07FF,0x07FF,0x07FF,0x07FF,0x07FF,0x07FF,0x07FF,0x07FF,0x07FF,0x07FF,0x07FF,0x07FF
,0x07FF,0x07FF,0x07FF,0x07FF,0x07FF,0x07FF,0x07FF,0x07FF,0x07FF,0x07FF,0x07FF,0x07FF,0x07FF,0x07FF,0x07FF,0x07FF,0x07FF,0x07FF,0x07FF,0x07FF,0x07FF,0x07FF,0x07FF,0x07FF,0x07FF,0x07FF,0x07FF,0x07FF,0x07FF,0x07FF,0x07FF,0x07FF,0x08,0x00,0x00,0x00,0x00,0x00,0x00,0x00,0x00,0x00,0x00,0x00,0x00,0x00,0x00,0x00,0x00,0x00,0x00,0x00,0x07FF,0x07FF,0x07FF,0x07FF,0x07FF,0x07FF,0x07FF,0x07FF,0x07FF,0x07FF,0x07FF,0x07FF,0x07FF
,0x07FF,0x07FF,0x07FF,0x07FF,0x07FF,0x07FF,0x07FF,0x07FF,0x07FF,0x07FF,0x07FF,0x07FF,0x07FF,0x07FF,0x07FF,0x07FF,0x07FF,0x07FF,0x07FF,0x07FF,0x07FF,0x07FF,0x07FF,0x07FF,0x07FF,0x07FF,0x07FF,0x07FF,0x07FF,0x07FF,0x07FF,0x07FF,0x08,0x00,0x00,0x00,0x00,0x00,0x00,0x00,0x00,0x00,0x00,0x00,0x00,0x00,0x00,0x00,0x00,0x00,0x00,0x00,0x07FF,0x07FF,0x07FF,0x07FF,0x07FF,0x07FF,0x07FF,0x07FF,0x07FF,0x07FF,0x07FF,0x07FF,0x07FF
,0x07FF,0x07FF,0x07FF,0x07FF,0x07FF,0x07FF,0x07FF,0x07FF,0x07FF,0x07FF,0x07FF,0x07FF,0x07FF,0x07FF,0x07FF,0x07FF,0x07FF,0x07FF,0x07FF,0x07FF,0x07FF,0x07FF,0x07FF,0x07FF,0x07FF,0x07FF,0x07FF,0x07FF,0x07FF,0x07FF,0x07FF,0x07FF,0x08,0x00,0x00,0x00,0x00,0x00,0x00,0x00,0x00,0x00,0x00,0x00,0x00,0x00,0x00,0x00,0x00,0x00,0x00,0x00,0x07FF,0x07FF,0x07FF,0x07FF,0x07FF,0x07FF,0x07FF,0x07FF,0x07FF,0x07FF,0x07FF,0x07FF,0x07FF
,0x07FF,0x07FF,0x07FF,0x07FF,0x07FF,0x07FF,0x07FF,0x07FF,0x07FF,0x07FF,0x07FF,0x07FF,0x07FF,0x07FF,0x07FF,0x07FF,0x07FF,0x07FF,0x07FF,0x07FF,0x07FF,0x07FF,0x07FF,0x07FF,0x07FF,0x07FF,0x07FF,0x07FF,0x07FF,0x07FF,0x07FF,0x07FF,0x08,0x00,0x00,0x00,0x00,0x00,0x00,0x00,0x00,0x00,0x00,0x00,0x00,0x00,0x00,0x00,0x00,0x00,0x00,0x00,0x07FF,0x07FF,0x07FF,0x07FF,0x07FF,0x07FF,0x07FF,0x07FF,0x07FF,0x07FF,0x07FF,0x07FF,0x07FF
,0x07FF,0x07FF,0x07FF,0x07FF,0x07FF,0x07FF,0x07FF,0x07FF,0x07FF,0x07FF,0x07FF,0x07FF,0x07FF,0x07FF,0x07FF,0x07FF,0x07FF,0x07FF,0x07FF,0x07FF,0x07FF,0x07FF,0x07FF,0x07FF,0x07FF,0x07FF,0x07FF,0x07FF,0x07FF,0x07FF,0x07FF,0x07FF,0x11,0x0c,0x00,0xb6,0xb6,0x6d,0x00,0x0c,0x0c,0x0c,0x0c,0x0c,0x00,0x49,0xb6,0xb6,0x00,0x08,0x0c,0x0c,0x07FF,0x07FF,0x07FF,0x07FF,0x07FF,0x07FF,0x07FF,0x07FF,0x07FF,0x07FF,0x07FF,0x07FF,0x07FF
,0x07FF,0x07FF,0x07FF,0x07FF,0x07FF,0x07FF,0x07FF,0x07FF,0x07FF,0x07FF,0x07FF,0x07FF,0x07FF,0x07FF,0x07FF,0x07FF,0x07FF,0x07FF,0x07FF,0x07FF,0x07FF,0x07FF,0x07FF,0x07FF,0x07FF,0x07FF,0x07FF,0x07FF,0x07FF,0x07FF,0x07FF,0x07FF,0x07FF,0x10,0x00,0xff,0xff,0xb6,0x00,0x07FF,0x07FF,0x07FF,0x07FF,0x07FF,0x04,0x6d,0xff,0xff,0x00,0x0c,0x07FF,0x07FF,0x07FF,0x07FF,0x07FF,0x07FF,0x07FF,0x07FF,0x07FF,0x07FF,0x07FF,0x07FF,0x07FF,0x07FF,0x07FF
,0x07FF,0x07FF,0x07FF,0x07FF,0x07FF,0x07FF,0x07FF,0x07FF,0x07FF,0x07FF,0x07FF,0x07FF,0x07FF,0x07FF,0x07FF,0x07FF,0x07FF,0x07FF,0x07FF,0x07FF,0x07FF,0x07FF,0x07FF,0x07FF,0x07FF,0x07FF,0x07FF,0x07FF,0x07FF,0x07FF,0x07FF,0x07FF,0x07FF,0x10,0x00,0xff,0xff,0xb6,0x00,0x07FF,0x07FF,0x07FF,0x07FF,0x07FF,0x04,0x6d,0xff,0xff,0x00,0x0c,0x07FF,0x07FF,0x07FF,0x07FF,0x07FF,0x07FF,0x07FF,0x07FF,0x07FF,0x07FF,0x07FF,0x07FF,0x07FF,0x07FF,0x07FF
,0x07FF,0x07FF,0x07FF,0x07FF,0x07FF,0x07FF,0x07FF,0x07FF,0x07FF,0x07FF,0x07FF,0x07FF,0x07FF,0x07FF,0x07FF,0x07FF,0x07FF,0x07FF,0x07FF,0x07FF,0x07FF,0x07FF,0x07FF,0x07FF,0x07FF,0x07FF,0x07FF,0x07FF,0x07FF,0x07FF,0x07FF,0x07FF,0x07FF,0x10,0x00,0xff,0xff,0xb6,0x00,0x07FF,0x07FF,0x07FF,0x07FF,0x07FF,0x04,0x6d,0xff,0xff,0x00,0x0c,0x07FF,0x07FF,0x07FF,0x07FF,0x07FF,0x07FF,0x07FF,0x07FF,0x07FF,0x07FF,0x07FF,0x07FF,0x07FF,0x07FF,0x07FF
,0x07FF,0x07FF,0x07FF,0x07FF,0x07FF,0x07FF,0x07FF,0x07FF,0x07FF,0x07FF,0x07FF,0x07FF,0x07FF,0x07FF,0x07FF,0x07FF,0x07FF,0x07FF,0x07FF,0x07FF,0x07FF,0x07FF,0x07FF,0x07FF,0x07FF,0x07FF,0x07FF,0x07FF,0x07FF,0x07FF,0x07FF,0x07FF,0x07FF,0x10,0x00,0xff,0xff,0xb6,0x00,0x07FF,0x07FF,0x07FF,0x07FF,0x07FF,0x04,0x6d,0xff,0xff,0x00,0x0c,0x07FF,0x07FF,0x07FF,0x07FF,0x07FF,0x07FF,0x07FF,0x07FF,0x07FF,0x07FF,0x07FF,0x07FF,0x07FF,0x07FF,0x07FF
,0x07FF,0x07FF,0x07FF,0x07FF,0x07FF,0x07FF,0x07FF,0x07FF,0x07FF,0x07FF,0x07FF,0x07FF,0x07FF,0x07FF,0x07FF,0x07FF,0x07FF,0x07FF,0x07FF,0x07FF,0x07FF,0x07FF,0x07FF,0x07FF,0x07FF,0x07FF,0x07FF,0x07FF,0x07FF,0x07FF,0x07FF,0x07FF,0x07FF,0x10,0x00,0xff,0xff,0xb6,0x00,0x07FF,0x07FF,0x07FF,0x07FF,0x07FF,0x04,0x6d,0xff,0xff,0x00,0x0c,0x07FF,0x07FF,0x07FF,0x07FF,0x07FF,0x07FF,0x07FF,0x07FF,0x07FF,0x07FF,0x07FF,0x07FF,0x07FF,0x07FF,0x07FF
,0x07FF,0x07FF,0x07FF,0x07FF,0x07FF,0x07FF,0x07FF,0x07FF,0x07FF,0x07FF,0x07FF,0x07FF,0x07FF,0x07FF,0x07FF,0x07FF,0x07FF,0x07FF,0x07FF,0x07FF,0x07FF,0x07FF,0x07FF,0x07FF,0x07FF,0x07FF,0x07FF,0x07FF,0x07FF,0x07FF,0x07FF,0x07FF,0x07FF,0x10,0x00,0xff,0xff,0xb6,0x00,0x07FF,0x07FF,0x07FF,0x07FF,0x07FF,0x04,0x6d,0xff,0xff,0x00,0x0c,0x07FF,0x07FF,0x07FF,0x07FF,0x07FF,0x07FF,0x07FF,0x07FF,0x07FF,0x07FF,0x07FF,0x07FF,0x07FF,0x07FF,0x07FF
,0x07FF,0x07FF,0x07FF,0x07FF,0x07FF,0x07FF,0x07FF,0x07FF,0x07FF,0x07FF,0x07FF,0x07FF,0x07FF,0x07FF,0x07FF,0x07FF,0x07FF,0x07FF,0x07FF,0x07FF,0x07FF,0x07FF,0x07FF,0x07FF,0x07FF,0x07FF,0x07FF,0x07FF,0x07FF,0x07FF,0x07FF,0x07FF,0x07FF,0x10,0x00,0xff,0xff,0xb6,0x00,0x07FF,0x07FF,0x07FF,0x07FF,0x07FF,0x04,0x6d,0xff,0xff,0x00,0x0c,0x07FF,0x07FF,0x07FF,0x07FF,0x07FF,0x07FF,0x07FF,0x07FF,0x07FF,0x07FF,0x07FF,0x07FF,0x07FF,0x07FF,0x07FF
,0x07FF,0x07FF,0x07FF,0x07FF,0x07FF,0x07FF,0x07FF,0x07FF,0x07FF,0x07FF,0x07FF,0x07FF,0x07FF,0x07FF,0x07FF,0x07FF,0x07FF,0x07FF,0x07FF,0x07FF,0x07FF,0x07FF,0x07FF,0x07FF,0x07FF,0x07FF,0x07FF,0x07FF,0x07FF,0x07FF,0x07FF,0x07FF,0x07FF,0x10,0x00,0xff,0xff,0xb6,0x00,0x07FF,0x07FF,0x07FF,0x07FF,0x07FF,0x04,0x6d,0xff,0xff,0x00,0x0c,0x07FF,0x07FF,0x07FF,0x07FF,0x07FF,0x07FF,0x07FF,0x07FF,0x07FF,0x07FF,0x07FF,0x07FF,0x07FF,0x07FF,0x07FF
,0x07FF,0x07FF,0x07FF,0x07FF,0x07FF,0x07FF,0x07FF,0x07FF,0x07FF,0x07FF,0x07FF,0x07FF,0x07FF,0x07FF,0x07FF,0x07FF,0x07FF,0x07FF,0x07FF,0x07FF,0x07FF,0x07FF,0x07FF,0x07FF,0x07FF,0x07FF,0x07FF,0x07FF,0x07FF,0x07FF,0x07FF,0x07FF,0x07FF,0x10,0x00,0xff,0xff,0xb6,0x00,0x07FF,0x07FF,0x07FF,0x07FF,0x07FF,0x04,0x6d,0xff,0xff,0x00,0x0c,0x07FF,0x07FF,0x07FF,0x07FF,0x07FF,0x07FF,0x07FF,0x07FF,0x07FF,0x07FF,0x07FF,0x07FF,0x07FF,0x07FF,0x07FF
,0x07FF,0x07FF,0x07FF,0x07FF,0x07FF,0x07FF,0x07FF,0x07FF,0x07FF,0x07FF,0x07FF,0x07FF,0x07FF,0x07FF,0x07FF,0x07FF,0x07FF,0x07FF,0x07FF,0x07FF,0x07FF,0x07FF,0x07FF,0x07FF,0x07FF,0x07FF,0x07FF,0x07FF,0x07FF,0x07FF,0x07FF,0x07FF,0x07FF,0x10,0x00,0xff,0xff,0xb6,0x00,0x07FF,0x07FF,0x07FF,0x07FF,0x07FF,0x04,0x6d,0xff,0xff,0x00,0x0c,0x07FF,0x07FF,0x07FF,0x07FF,0x07FF,0x07FF,0x07FF,0x07FF,0x07FF,0x07FF,0x07FF,0x07FF,0x07FF,0x07FF,0x07FF
,0x07FF,0x07FF,0x07FF,0x07FF,0x07FF,0x07FF,0x07FF,0x07FF,0x07FF,0x07FF,0x07FF,0x07FF,0x07FF,0x07FF,0x07FF,0x07FF,0x07FF,0x07FF,0x07FF,0x07FF,0x07FF,0x07FF,0x07FF,0x07FF,0x07FF,0x07FF,0x07FF,0x11,0x11,0x11,0x11,0x11,0x11,0x0c,0x00,0xdb,0xdb,0x92,0x00,0x11,0x07FF,0x07FF,0x07FF,0x11,0x00,0x6d,0xdb,0xdb,0x00,0x08,0x11,0x07FF,0x07FF,0x07FF,0x07FF,0x07FF,0x07FF,0x07FF,0x07FF,0x07FF,0x07FF,0x07FF,0x07FF,0x07FF,0x07FF
,0x07FF,0x07FF,0x07FF,0x07FF,0x07FF,0x07FF,0x07FF,0x07FF,0x07FF,0x07FF,0x07FF,0x07FF,0x07FF,0x07FF,0x07FF,0x07FF,0x07FF,0x07FF,0x07FF,0x07FF,0x07FF,0x07FF,0x07FF,0x07FF,0x07FF,0x07FF,0x07FF,0x04,0x00,0x00,0x00,0x00,0x00,0x00,0x00,0x00,0x00,0x00,0x00,0x00,0x0c,0x07FF,0x11,0x00,0x00,0x00,0x00,0x00,0x00,0x00,0x04,0x07FF,0x07FF,0x07FF,0x07FF,0x07FF,0x07FF,0x07FF,0x07FF,0x07FF,0x07FF,0x07FF,0x07FF,0x07FF,0x07FF
,0x07FF,0x07FF,0x07FF,0x07FF,0x07FF,0x07FF,0x07FF,0x07FF,0x07FF,0x07FF,0x07FF,0x07FF,0x07FF,0x07FF,0x07FF,0x07FF,0x07FF,0x07FF,0x07FF,0x07FF,0x07FF,0x07FF,0x07FF,0x07FF,0x07FF,0x07FF,0x07FF,0x04,0x20,0x88,0x88,0x88,0x88,0x88,0x88,0x88,0x88,0x88,0x88,0x00,0x0c,0x07FF,0x11,0x00,0x64,0x88,0x88,0x88,0x88,0x20,0x04,0x07FF,0x07FF,0x07FF,0x07FF,0x07FF,0x07FF,0x07FF,0x07FF,0x07FF,0x07FF,0x07FF,0x07FF,0x07FF,0x07FF
,0x07FF,0x07FF,0x07FF,0x07FF,0x07FF,0x07FF,0x07FF,0x07FF,0x07FF,0x07FF,0x07FF,0x07FF,0x07FF,0x07FF,0x07FF,0x07FF,0x07FF,0x07FF,0x07FF,0x07FF,0x07FF,0x07FF,0x07FF,0x07FF,0x07FF,0x07FF,0x07FF,0x04,0x24,0x88,0x88,0x88,0x88,0x88,0x88,0x88,0x88,0x88,0x88,0x00,0x0c,0x07FF,0x11,0x00,0x68,0x88,0x88,0x88,0x88,0x24,0x04,0x07FF,0x07FF,0x07FF,0x07FF,0x07FF,0x07FF,0x07FF,0x07FF,0x07FF,0x07FF,0x07FF,0x07FF,0x07FF,0x07FF
,0x07FF,0x07FF,0x07FF,0x07FF,0x07FF,0x07FF,0x07FF,0x07FF,0x07FF,0x07FF,0x07FF,0x07FF,0x07FF,0x07FF,0x07FF,0x07FF,0x07FF,0x07FF,0x07FF,0x07FF,0x07FF,0x07FF,0x07FF,0x07FF,0x07FF,0x07FF,0x07FF,0x04,0x20,0x68,0x68,0x68,0x68,0x68,0x68,0x68,0x68,0x68,0x68,0x00,0x0c,0x07FF,0x11,0x00,0x44,0x68,0x68,0x68,0x68,0x20,0x04,0x07FF,0x07FF,0x07FF,0x07FF,0x07FF,0x07FF,0x07FF,0x07FF,0x07FF,0x07FF,0x07FF,0x07FF,0x07FF,0x07FF
,0x07FF,0x07FF,0x07FF,0x07FF,0x07FF,0x07FF,0x07FF,0x07FF,0x07FF,0x07FF,0x07FF,0x07FF,0x07FF,0x07FF,0x07FF,0x07FF,0x07FF,0x07FF,0x07FF,0x07FF,0x07FF,0x07FF,0x07FF,0x07FF,0x07FF,0x07FF,0x07FF,0x04,0x00,0x00,0x00,0x00,0x00,0x00,0x00,0x00,0x00,0x00,0x00,0x00,0x0c,0x07FF,0x11,0x00,0x00,0x00,0x00,0x00,0x00,0x00,0x04,0x07FF,0x07FF,0x07FF,0x07FF,0x07FF,0x07FF,0x07FF,0x07FF,0x07FF,0x07FF,0x07FF,0x07FF,0x07FF,0x07FF

};

const uint16_t image1[] = {
0x07FF,0x07FF,0x07FF,0x07FF,0x07FF,0x07FF,0x07FF,0x07FF,0x07FF,0x07FF,0x07FF,0x07FF,0x07FF,0x07FF,0x07FF,0x07FF,0x11,0x00,0x00,0x00,0x00,0x00,0x00,0x00,0x00,0x00,0x00,0x0c,0x07FF,0x07FF,0x07FF,0x07FF,0x07FF,0x07FF,0x07FF,0x07FF,0x07FF,0x07FF,0x07FF,0x07FF,0x07FF,0x07FF,0x07FF,0x07FF,0x07FF,0x07FF,0x07FF,0x07FF,0x07FF,0x07FF,0x07FF,0x07FF,0x07FF,0x07FF,0x07FF,0x07FF,0x07FF,0x07FF,0x07FF,0x07FF,0x07FF,0x07FF,0x07FF,0x07FF,0x07FF
,0x07FF,0x07FF,0x07FF,0x07FF,0x07FF,0x07FF,0x07FF,0x07FF,0x07FF,0x07FF,0x0c,0x04,0x04,0x07FF,0x07FF,0x0c,0x04,0xb4,0x24,0x00,0x00,0x00,0x00,0x00,0x24,0xb4,0x00,0x04,0x0c,0x07FF,0x07FF,0x08,0x04,0x04,0x04,0x04,0x0c,0x07FF,0x07FF,0x07FF,0x07FF,0x07FF,0x07FF,0x07FF,0x07FF,0x07FF,0x07FF,0x07FF,0x07FF,0x07FF,0x07FF,0x07FF,0x07FF,0x07FF,0x07FF,0x07FF,0x07FF,0x07FF,0x07FF,0x07FF,0x07FF,0x07FF,0x07FF,0x07FF,0x07FF
,0x07FF,0x07FF,0x07FF,0x07FF,0x07FF,0x07FF,0x07FF,0x07FF,0x07FF,0x07FF,0x08,0x00,0x00,0x0c,0x0c,0x04,0x00,0xfc,0x90,0x24,0x00,0x00,0x00,0x00,0x24,0x90,0x6c,0x20,0x04,0x0c,0x0c,0x00,0x24,0x6c,0x6c,0x00,0x0c,0x07FF,0x07FF,0x07FF,0x07FF,0x07FF,0x07FF,0x07FF,0x07FF,0x07FF,0x07FF,0x07FF,0x07FF,0x07FF,0x07FF,0x07FF,0x07FF,0x07FF,0x07FF,0x07FF,0x07FF,0x07FF,0x07FF,0x07FF,0x07FF,0x07FF,0x07FF,0x07FF,0x07FF
,0x07FF,0x07FF,0x07FF,0x07FF,0x07FF,0x07FF,0x07FF,0x07FF,0x07FF,0x07FF,0x08,0x00,0x24,0x00,0x00,0x00,0x24,0xd8,0xd8,0x6c,0x24,0x24,0x24,0x24,0x24,0x24,0xd8,0x44,0x00,0x24,0x24,0x24,0x90,0xfc,0xd8,0x00,0x0c,0x07FF,0x07FF,0x07FF,0x07FF,0x07FF,0x07FF,0x07FF,0x07FF,0x07FF,0x07FF,0x07FF,0x07FF,0x07FF,0x07FF,0x07FF,0x07FF,0x07FF,0x07FF,0x07FF,0x07FF,0x07FF,0x07FF,0x07FF,0x07FF,0x07FF,0x07FF,0x07FF,0x07FF
,0x07FF,0x07FF,0x07FF,0x07FF,0x07FF,0x07FF,0x07FF,0x07FF,0x07FF,0x07FF,0x08,0x48,0xfc,0x00,0x00,0x6c,0xf8,0x00,0x00,0x6d,0xff,0xff,0xff,0xff,0xff,0xff,0x00,0x00,0x6c,0xfc,0xfc,0xfc,0xfc,0xd8,0x00,0x00,0x0c,0x07FF,0x07FF,0x07FF,0x07FF,0x07FF,0x07FF,0x07FF,0x07FF,0x07FF,0x07FF,0x07FF,0x07FF,0x07FF,0x07FF,0x07FF,0x07FF,0x07FF,0x07FF,0x07FF,0x07FF,0x07FF,0x07FF,0x07FF,0x07FF,0x07FF,0x07FF,0x07FF,0x07FF
,0x07FF,0x07FF,0x07FF,0x07FF,0x07FF,0x07FF,0x07FF,0x07FF,0x07FF,0x07FF,0x08,0x00,0x24,0xd8,0xd8,0x90,0x24,0xdb,0xdb,0xff,0xff,0xff,0xff,0xff,0xff,0xff,0xdb,0xdb,0x92,0x24,0xfc,0xfc,0x90,0x00,0x00,0x10,0x07FF,0x07FF,0x07FF,0x07FF,0x07FF,0x07FF,0x07FF,0x07FF,0x07FF,0x07FF,0x07FF,0x07FF,0x07FF,0x07FF,0x07FF,0x07FF,0x07FF,0x07FF,0x07FF,0x07FF,0x07FF,0x07FF,0x07FF,0x07FF,0x07FF,0x07FF,0x07FF,0x07FF,0x07FF
,0x07FF,0x07FF,0x07FF,0x07FF,0x07FF,0x07FF,0x07FF,0x07FF,0x07FF,0x07FF,0x10,0x08,0x00,0xfc,0x90,0x6c,0x92,0xff,0x92,0x6d,0x92,0xff,0xff,0xb6,0x6d,0x6d,0xff,0xff,0xdb,0x92,0x6c,0x6c,0x24,0x00,0x0c,0x07FF,0x07FF,0x07FF,0x07FF,0x07FF,0x07FF,0x07FF,0x07FF,0x07FF,0x07FF,0x07FF,0x07FF,0x07FF,0x07FF,0x07FF,0x07FF,0x07FF,0x07FF,0x07FF,0x07FF,0x07FF,0x07FF,0x07FF,0x07FF,0x07FF,0x07FF,0x07FF,0x07FF,0x07FF,0x07FF
,0x07FF,0x07FF,0x07FF,0x07FF,0x07FF,0x07FF,0x07FF,0x07FF,0x07FF,0x07FF,0x07FF,0x0c,0x00,0xb4,0x24,0x6d,0xff,0xff,0x24,0x00,0x24,0xff,0xff,0x6d,0x00,0x00,0xff,0xff,0xff,0xff,0x00,0x00,0x00,0x08,0x07FF,0x07FF,0x07FF,0x07FF,0x07FF,0x07FF,0x07FF,0x07FF,0x07FF,0x07FF,0x07FF,0x07FF,0x07FF,0x07FF,0x07FF,0x07FF,0x07FF,0x07FF,0x07FF,0x07FF,0x07FF,0x07FF,0x07FF,0x07FF,0x07FF,0x07FF,0x07FF,0x07FF,0x07FF,0x07FF,0x07FF
,0x07FF,0x07FF,0x07FF,0x07FF,0x07FF,0x07FF,0x07FF,0x07FF,0x07FF,0x07FF,0x07FF,0x0c,0x00,0x00,0x00,0x6d,0xff,0xff,0x24,0x00,0x24,0xff,0xff,0x6d,0x00,0x00,0xff,0xff,0xff,0xff,0x00,0x00,0x08,0x07FF,0x07FF,0x07FF,0x07FF,0x07FF,0x07FF,0x07FF,0x07FF,0x07FF,0x07FF,0x07FF,0x07FF,0x07FF,0x07FF,0x07FF,0x07FF,0x07FF,0x07FF,0x07FF,0x07FF,0x07FF,0x07FF,0x07FF,0x07FF,0x07FF,0x07FF,0x07FF,0x07FF,0x07FF,0x07FF,0x07FF,0x07FF
,0x07FF,0x07FF,0x07FF,0x07FF,0x07FF,0x07FF,0x07FF,0x07FF,0x07FF,0x07FF,0x07FF,0x07FF,0x07FF,0x07FF,0x04,0x6d,0xff,0xff,0xff,0xff,0xff,0xff,0xff,0xff,0xff,0xff,0xff,0xff,0xff,0xff,0x00,0x10,0x07FF,0x07FF,0x07FF,0x07FF,0x07FF,0x07FF,0x07FF,0x07FF,0x07FF,0x07FF,0x07FF,0x07FF,0x07FF,0x07FF,0x07FF,0x07FF,0x07FF,0x07FF,0x07FF,0x07FF,0x07FF,0x07FF,0x07FF,0x07FF,0x07FF,0x07FF,0x07FF,0x07FF,0x07FF,0x07FF,0x07FF,0x07FF,0x07FF
,0x07FF,0x07FF,0x07FF,0x07FF,0x07FF,0x07FF,0x07FF,0x07FF,0x07FF,0x07FF,0x07FF,0x07FF,0x07FF,0x07FF,0x04,0x6d,0xff,0xff,0xff,0xff,0xff,0xff,0xff,0xff,0xff,0xff,0xff,0xff,0xff,0xff,0x00,0x10,0x07FF,0x07FF,0x07FF,0x07FF,0x07FF,0x07FF,0x07FF,0x07FF,0x07FF,0x07FF,0x07FF,0x07FF,0x07FF,0x07FF,0x07FF,0x07FF,0x07FF,0x07FF,0x07FF,0x07FF,0x07FF,0x07FF,0x07FF,0x07FF,0x07FF,0x07FF,0x07FF,0x07FF,0x07FF,0x07FF,0x07FF,0x07FF,0x07FF
,0x07FF,0x07FF,0x07FF,0x07FF,0x07FF,0x07FF,0x07FF,0x07FF,0x07FF,0x07FF,0x07FF,0x07FF,0x07FF,0x07FF,0x04,0x6d,0xff,0xff,0xb6,0xdb,0xff,0xff,0xff,0xff,0xff,0xff,0x92,0xdb,0xff,0xff,0x00,0x10,0x07FF,0x07FF,0x07FF,0x07FF,0x07FF,0x07FF,0x07FF,0x07FF,0x07FF,0x07FF,0x07FF,0x07FF,0x07FF,0x07FF,0x07FF,0x07FF,0x07FF,0x07FF,0x07FF,0x07FF,0x07FF,0x07FF,0x07FF,0x07FF,0x07FF,0x07FF,0x07FF,0x07FF,0x07FF,0x07FF,0x07FF,0x07FF,0x07FF
,0x07FF,0x07FF,0x07FF,0x07FF,0x07FF,0x07FF,0x07FF,0x07FF,0x07FF,0x07FF,0x07FF,0x07FF,0x07FF,0x07FF,0x04,0x6d,0xff,0xff,0x49,0x6d,0xff,0xff,0xff,0xff,0xff,0xdb,0x24,0xb6,0xff,0xff,0x00,0x10,0x07FF,0x07FF,0x07FF,0x07FF,0x07FF,0x07FF,0x07FF,0x07FF,0x07FF,0x07FF,0x07FF,0x07FF,0x07FF,0x07FF,0x07FF,0x07FF,0x07FF,0x07FF,0x07FF,0x07FF,0x07FF,0x07FF,0x07FF,0x07FF,0x07FF,0x07FF,0x07FF,0x07FF,0x07FF,0x07FF,0x07FF,0x07FF,0x07FF
,0x07FF,0x07FF,0x07FF,0x07FF,0x07FF,0x07FF,0x07FF,0x07FF,0x07FF,0x07FF,0x07FF,0x07FF,0x07FF,0x07FF,0x04,0x6d,0xff,0xff,0xff,0x6d,0x24,0xff,0xff,0xff,0xb6,0x00,0xff,0xff,0xff,0xff,0x00,0x10,0x07FF,0x07FF,0x07FF,0x07FF,0x07FF,0x07FF,0x07FF,0x07FF,0x07FF,0x07FF,0x07FF,0x07FF,0x07FF,0x07FF,0x07FF,0x07FF,0x07FF,0x07FF,0x07FF,0x07FF,0x07FF,0x07FF,0x07FF,0x07FF,0x07FF,0x07FF,0x07FF,0x07FF,0x07FF,0x07FF,0x07FF,0x07FF,0x07FF
,0x07FF,0x07FF,0x07FF,0x07FF,0x07FF,0x07FF,0x07FF,0x07FF,0x07FF,0x07FF,0x07FF,0x07FF,0x07FF,0x07FF,0x11,0x2c,0x24,0xff,0xff,0xff,0xb6,0x24,0x24,0x24,0x49,0xdb,0xff,0xff,0xb6,0x24,0x11,0x07FF,0x07FF,0x07FF,0x07FF,0x07FF,0x07FF,0x07FF,0x07FF,0x07FF,0x07FF,0x07FF,0x07FF,0x07FF,0x07FF,0x07FF,0x07FF,0x07FF,0x07FF,0x07FF,0x07FF,0x07FF,0x07FF,0x07FF,0x07FF,0x07FF,0x07FF,0x07FF,0x07FF,0x07FF,0x07FF,0x07FF,0x07FF,0x07FF,0x07FF
,0x07FF,0x07FF,0x07FF,0x07FF,0x07FF,0x07FF,0x07FF,0x07FF,0x07FF,0x07FF,0x07FF,0x07FF,0x07FF,0x07FF,0x07FF,0x10,0x0c,0x6d,0x6d,0xb6,0xff,0x92,0x92,0x92,0xb6,0xff,0x6d,0x6d,0x4d,0x0c,0x07FF,0x07FF,0x07FF,0x07FF,0x07FF,0x07FF,0x07FF,0x07FF,0x07FF,0x07FF,0x07FF,0x07FF,0x07FF,0x07FF,0x07FF,0x07FF,0x07FF,0x07FF,0x07FF,0x07FF,0x07FF,0x07FF,0x07FF,0x07FF,0x07FF,0x07FF,0x07FF,0x07FF,0x07FF,0x07FF,0x07FF,0x07FF,0x07FF,0x07FF,0x07FF
,0x07FF,0x07FF,0x07FF,0x07FF,0x07FF,0x07FF,0x07FF,0x07FF,0x07FF,0x07FF,0x07FF,0x07FF,0x07FF,0x07FF,0x07FF,0x07FF,0x15,0x04,0x04,0x4d,0xb6,0xb6,0xb6,0xb6,0xb6,0xb6,0x04,0x04,0x0c,0x07FF,0x07FF,0x07FF,0x07FF,0x07FF,0x07FF,0x07FF,0x07FF,0x07FF,0x07FF,0x07FF,0x07FF,0x07FF,0x07FF,0x07FF,0x07FF,0x07FF,0x07FF,0x07FF,0x07FF,0x07FF,0x07FF,0x07FF,0x07FF,0x07FF,0x07FF,0x07FF,0x07FF,0x07FF,0x07FF,0x07FF,0x07FF,0x07FF,0x07FF,0x07FF,0x07FF
,0x07FF,0x07FF,0x07FF,0x07FF,0x07FF,0x07FF,0x07FF,0x07FF,0x07FF,0x07FF,0x07FF,0x07FF,0x07FF,0x07FF,0x07FF,0x07FF,0x07FF,0x07FF,0x07FF,0x08,0x00,0x00,0x00,0x00,0x00,0x00,0x07FF,0x07FF,0x07FF,0x07FF,0x07FF,0x07FF,0x07FF,0x07FF,0x07FF,0x07FF,0x07FF,0x07FF,0x07FF,0x07FF,0x07FF,0x07FF,0x07FF,0x07FF,0x07FF,0x07FF,0x07FF,0x07FF,0x07FF,0x07FF,0x07FF,0x07FF,0x07FF,0x07FF,0x07FF,0x07FF,0x07FF,0x07FF,0x07FF,0x07FF,0x07FF,0x07FF,0x07FF,0x07FF,0x07FF
,0x07FF,0x07FF,0x07FF,0x07FF,0x07FF,0x07FF,0x07FF,0x07FF,0x07FF,0x07FF,0x07FF,0x07FF,0x07FF,0x07FF,0x07FF,0x07FF,0x07FF,0x07FF,0x07FF,0x08,0x00,0x60,0x60,0x60,0x45,0x00,0x07FF,0x07FF,0x07FF,0x07FF,0x07FF,0x07FF,0x07FF,0x07FF,0x07FF,0x07FF,0x07FF,0x07FF,0x07FF,0x07FF,0x07FF,0x07FF,0x07FF,0x07FF,0x07FF,0x07FF,0x07FF,0x07FF,0x07FF,0x07FF,0x07FF,0x07FF,0x07FF,0x07FF,0x07FF,0x07FF,0x07FF,0x07FF,0x07FF,0x07FF,0x07FF,0x07FF,0x07FF,0x07FF,0x07FF
,0x07FF,0x07FF,0x07FF,0x07FF,0x07FF,0x07FF,0x07FF,0x07FF,0x07FF,0x07FF,0x07FF,0x07FF,0x07FF,0x07FF,0x07FF,0x07FF,0x07FF,0x07FF,0x07FF,0x08,0x00,0x60,0x60,0x60,0x45,0x00,0x07FF,0x07FF,0x07FF,0x07FF,0x07FF,0x07FF,0x07FF,0x07FF,0x07FF,0x07FF,0x07FF,0x07FF,0x07FF,0x07FF,0x07FF,0x07FF,0x07FF,0x07FF,0x07FF,0x07FF,0x07FF,0x07FF,0x07FF,0x07FF,0x07FF,0x07FF,0x07FF,0x07FF,0x07FF,0x07FF,0x07FF,0x07FF,0x07FF,0x07FF,0x07FF,0x07FF,0x07FF,0x07FF,0x07FF
,0x07FF,0x07FF,0x07FF,0x07FF,0x07FF,0x07FF,0x07FF,0x07FF,0x07FF,0x07FF,0x07FF,0x07FF,0x07FF,0x07FF,0x07FF,0x07FF,0x07FF,0x07FF,0x07FF,0x08,0x00,0x60,0x60,0x60,0x45,0x00,0x07FF,0x07FF,0x07FF,0x07FF,0x07FF,0x07FF,0x07FF,0x07FF,0x07FF,0x07FF,0x07FF,0x07FF,0x07FF,0x07FF,0x07FF,0x07FF,0x07FF,0x07FF,0x07FF,0x07FF,0x07FF,0x07FF,0x07FF,0x07FF,0x07FF,0x07FF,0x07FF,0x07FF,0x07FF,0x07FF,0x07FF,0x07FF,0x07FF,0x07FF,0x07FF,0x07FF,0x07FF,0x07FF,0x07FF
,0x07FF,0x07FF,0x07FF,0x07FF,0x07FF,0x07FF,0x07FF,0x07FF,0x07FF,0x11,0x11,0x11,0x11,0x11,0x11,0x11,0x11,0x11,0x11,0x08,0x00,0x60,0x60,0x60,0x45,0x00,0x11,0x11,0x11,0x11,0x11,0x11,0x11,0x11,0x11,0x11,0x07FF,0x07FF,0x07FF,0x07FF,0x07FF,0x07FF,0x07FF,0x07FF,0x07FF,0x07FF,0x07FF,0x07FF,0x07FF,0x07FF,0x07FF,0x07FF,0x07FF,0x07FF,0x07FF,0x07FF,0x07FF,0x07FF,0x07FF,0x07FF,0x07FF,0x07FF,0x07FF,0x07FF,0x07FF
,0x07FF,0x07FF,0x07FF,0x07FF,0x07FF,0x07FF,0x07FF,0x07FF,0x07FF,0x00,0x00,0x00,0x00,0x00,0x00,0x00,0x00,0x00,0x00,0x00,0x00,0x60,0x60,0x60,0x45,0x00,0x00,0x00,0x00,0x00,0x00,0x00,0x00,0x00,0x00,0x00,0x0c,0x07FF,0x07FF,0x07FF,0x07FF,0x07FF,0x07FF,0x07FF,0x07FF,0x07FF,0x07FF,0x07FF,0x07FF,0x07FF,0x07FF,0x07FF,0x07FF,0x07FF,0x07FF,0x07FF,0x07FF,0x07FF,0x07FF,0x07FF,0x07FF,0x07FF,0x07FF,0x07FF,0x07FF
,0x07FF,0x07FF,0x07FF,0x07FF,0x07FF,0x07FF,0x07FF,0x10,0x00,0x45,0x46,0x46,0x46,0x46,0x46,0x46,0x46,0x46,0x46,0x46,0x60,0x60,0x60,0x60,0x60,0x46,0x46,0x46,0x46,0x46,0x46,0x46,0x46,0x46,0x46,0x46,0x20,0x08,0x07FF,0x07FF,0x07FF,0x07FF,0x07FF,0x07FF,0x07FF,0x07FF,0x07FF,0x07FF,0x07FF,0x07FF,0x07FF,0x07FF,0x07FF,0x07FF,0x07FF,0x07FF,0x07FF,0x07FF,0x07FF,0x07FF,0x07FF,0x07FF,0x07FF,0x07FF,0x07FF
,0x07FF,0x07FF,0x07FF,0x07FF,0x07FF,0x07FF,0x0c,0x08,0x21,0x60,0x60,0x60,0x60,0x60,0x60,0x60,0x60,0x60,0x60,0x60,0x60,0x60,0x60,0x60,0x60,0x60,0x60,0x60,0x60,0x60,0x60,0x60,0x60,0x60,0x60,0x60,0x45,0x25,0x08,0x07FF,0x07FF,0x07FF,0x07FF,0x07FF,0x07FF,0x07FF,0x07FF,0x07FF,0x07FF,0x07FF,0x07FF,0x07FF,0x07FF,0x07FF,0x07FF,0x07FF,0x07FF,0x07FF,0x07FF,0x07FF,0x07FF,0x07FF,0x07FF,0x07FF,0x07FF
,0x07FF,0x07FF,0x07FF,0x07FF,0x07FF,0x10,0x08,0x21,0x60,0x60,0x60,0x60,0x60,0x60,0x60,0x60,0x60,0x60,0x60,0x60,0x60,0x60,0x60,0x60,0x60,0x60,0x60,0x60,0x60,0x60,0x60,0x60,0x60,0x60,0x60,0x60,0x60,0x45,0x00,0x0c,0x15,0x07FF,0x07FF,0x07FF,0x07FF,0x07FF,0x07FF,0x07FF,0x07FF,0x07FF,0x07FF,0x07FF,0x07FF,0x07FF,0x07FF,0x07FF,0x07FF,0x07FF,0x07FF,0x07FF,0x07FF,0x07FF,0x07FF,0x07FF,0x07FF
,0x07FF,0x07FF,0x07FF,0x07FF,0x07FF,0x04,0x21,0x60,0x60,0x60,0x60,0x60,0x60,0x60,0x60,0x60,0x60,0x60,0x60,0x60,0x60,0x60,0x60,0x60,0x60,0x60,0x60,0x60,0x60,0x60,0x60,0x60,0x60,0x60,0x60,0x60,0x60,0x60,0x60,0x00,0x0c,0x07FF,0x07FF,0x07FF,0x07FF,0x07FF,0x07FF,0x07FF,0x07FF,0x07FF,0x07FF,0x07FF,0x07FF,0x07FF,0x07FF,0x07FF,0x07FF,0x07FF,0x07FF,0x07FF,0x07FF,0x07FF,0x07FF,0x07FF,0x07FF
,0x07FF,0x07FF,0x07FF,0x11,0x00,0x45,0x60,0x60,0x60,0x60,0x60,0x60,0x60,0x60,0x60,0x60,0x60,0x60,0x60,0x60,0x60,0x60,0x60,0x60,0x60,0x60,0x60,0x60,0x60,0x60,0x60,0x60,0x60,0x60,0x60,0x60,0x60,0x60,0x60,0x60,0x20,0x08,0x07FF,0x07FF,0x07FF,0x07FF,0x07FF,0x07FF,0x07FF,0x07FF,0x07FF,0x07FF,0x07FF,0x07FF,0x07FF,0x07FF,0x07FF,0x07FF,0x07FF,0x07FF,0x07FF,0x07FF,0x07FF,0x07FF,0x07FF
,0x07FF,0x07FF,0x07FF,0x11,0x00,0x45,0x60,0x60,0x60,0x60,0x60,0x60,0x60,0x60,0x60,0x60,0x60,0x60,0x60,0x60,0x60,0x60,0x60,0x60,0x60,0x60,0x60,0x60,0x60,0x60,0x60,0x60,0x60,0x60,0x60,0x60,0x60,0x60,0x60,0x60,0x45,0x25,0x04,0x07FF,0x07FF,0x07FF,0x07FF,0x07FF,0x07FF,0x07FF,0x07FF,0x07FF,0x07FF,0x07FF,0x07FF,0x07FF,0x07FF,0x07FF,0x07FF,0x07FF,0x07FF,0x07FF,0x07FF,0x07FF,0x07FF
,0x07FF,0x07FF,0x07FF,0x11,0x00,0x45,0x60,0x60,0x60,0x60,0x60,0x60,0x21,0x21,0x60,0x60,0x60,0x60,0x60,0x60,0x60,0x60,0x60,0x60,0x60,0x60,0x60,0x60,0x60,0x60,0x60,0x45,0x21,0x45,0x60,0x60,0x60,0x60,0x60,0x60,0x45,0x20,0x00,0x07FF,0x07FF,0x07FF,0x07FF,0x07FF,0x07FF,0x07FF,0x07FF,0x07FF,0x07FF,0x07FF,0x07FF,0x07FF,0x07FF,0x07FF,0x07FF,0x07FF,0x07FF,0x07FF,0x07FF,0x07FF,0x07FF
,0x07FF,0x07FF,0x07FF,0x11,0x00,0x45,0x60,0x60,0x60,0x60,0x60,0x45,0x00,0x00,0x45,0x60,0x60,0x60,0x60,0x60,0x60,0x60,0x60,0x60,0x60,0x60,0x60,0x60,0x60,0x60,0x60,0x00,0x00,0x00,0x46,0x60,0x60,0x60,0x60,0x46,0x25,0x00,0x00,0x11,0x07FF,0x07FF,0x07FF,0x07FF,0x07FF,0x07FF,0x07FF,0x07FF,0x07FF,0x07FF,0x07FF,0x07FF,0x07FF,0x07FF,0x07FF,0x07FF,0x07FF,0x07FF,0x07FF,0x07FF,0x07FF
,0x07FF,0x07FF,0x07FF,0x11,0x00,0x45,0x60,0x60,0x60,0x60,0x60,0x45,0x00,0x00,0x45,0x60,0x60,0x60,0x60,0x60,0x60,0x60,0x60,0x60,0x60,0x60,0x60,0x60,0x60,0x60,0x60,0x00,0x08,0x10,0x00,0x60,0x60,0x60,0x60,0x00,0xb6,0x92,0x00,0x00,0x10,0x07FF,0x07FF,0x07FF,0x07FF,0x07FF,0x07FF,0x07FF,0x07FF,0x07FF,0x07FF,0x07FF,0x07FF,0x07FF,0x07FF,0x07FF,0x07FF,0x07FF,0x07FF,0x07FF,0x07FF
,0x07FF,0x07FF,0x07FF,0x11,0x00,0x45,0x60,0x60,0x60,0x60,0x60,0x45,0x00,0x00,0x45,0x60,0x60,0x60,0x60,0x60,0x60,0x60,0x60,0x60,0x60,0x60,0x60,0x60,0x60,0x60,0x60,0x00,0x08,0x07FF,0x11,0x00,0x45,0x45,0x00,0xdb,0xff,0xff,0xdb,0x00,0x00,0x0c,0x07FF,0x07FF,0x07FF,0x07FF,0x07FF,0x07FF,0x07FF,0x07FF,0x07FF,0x07FF,0x07FF,0x07FF,0x07FF,0x07FF,0x07FF,0x07FF,0x07FF,0x07FF,0x07FF
,0x07FF,0x07FF,0x07FF,0x11,0x00,0x45,0x60,0x60,0x60,0x60,0x60,0x45,0x00,0x00,0x45,0x60,0x60,0x60,0x60,0x60,0x60,0x60,0x60,0x60,0x60,0x60,0x60,0x60,0x60,0x60,0x60,0x00,0x08,0x07FF,0x07FF,0x0c,0x24,0x20,0x00,0xff,0xff,0xff,0xff,0x92,0x00,0x04,0x0c,0x07FF,0x07FF,0x07FF,0x07FF,0x07FF,0x07FF,0x07FF,0x07FF,0x07FF,0x07FF,0x07FF,0x07FF,0x07FF,0x07FF,0x07FF,0x07FF,0x07FF,0x07FF
,0x07FF,0x07FF,0x07FF,0x11,0x00,0x45,0x60,0x60,0x60,0x60,0x60,0x45,0x00,0x00,0x45,0x60,0x60,0x60,0x60,0x60,0x60,0x60,0x60,0x60,0x60,0x60,0x60,0x60,0x60,0x60,0x60,0x00,0x08,0x07FF,0x07FF,0x07FF,0x0c,0x04,0x00,0xb6,0xff,0xff,0xff,0xff,0x6d,0x24,0x00,0x0c,0x07FF,0x07FF,0x07FF,0x07FF,0x07FF,0x07FF,0x07FF,0x07FF,0x07FF,0x07FF,0x07FF,0x07FF,0x07FF,0x07FF,0x07FF,0x07FF,0x07FF
,0x07FF,0x07FF,0x07FF,0x11,0x00,0x45,0x60,0x60,0x60,0x60,0x60,0x45,0x00,0x00,0x45,0x60,0x60,0x60,0x60,0x60,0x60,0x60,0x60,0x60,0x60,0x60,0x60,0x60,0x60,0x60,0x60,0x00,0x08,0x07FF,0x07FF,0x07FF,0x07FF,0x0c,0x00,0x00,0xb6,0xff,0xff,0xff,0xff,0x6d,0x00,0x00,0x11,0x07FF,0x07FF,0x07FF,0x07FF,0x07FF,0x07FF,0x07FF,0x07FF,0x07FF,0x07FF,0x07FF,0x07FF,0x07FF,0x07FF,0x07FF,0x07FF
,0x07FF,0x07FF,0x07FF,0x11,0x00,0x45,0x60,0x60,0x60,0x60,0x60,0x45,0x00,0x00,0x45,0x60,0x60,0x60,0x60,0x60,0x60,0x60,0x60,0x60,0x60,0x60,0x60,0x60,0x60,0x60,0x60,0x00,0x08,0x07FF,0x07FF,0x07FF,0x07FF,0x07FF,0x07FF,0x00,0x00,0x6d,0xff,0xff,0xff,0xff,0xdb,0x00,0x00,0x0c,0x07FF,0x07FF,0x07FF,0x07FF,0x07FF,0x11,0x00,0x00,0x00,0x00,0x00,0x11,0x07FF,0x07FF,0x07FF
,0x07FF,0x07FF,0x07FF,0x11,0x00,0x00,0x00,0x00,0x00,0x00,0x00,0x00,0x00,0x00,0x45,0x60,0x60,0x60,0x60,0x60,0x60,0x60,0x60,0x60,0x60,0x60,0x60,0x60,0x60,0x60,0x60,0x00,0x08,0x07FF,0x07FF,0x07FF,0x07FF,0x07FF,0x07FF,0x0c,0x04,0x00,0x49,0xff,0xff,0xff,0xdb,0x00,0x00,0x00,0x08,0x07FF,0x07FF,0x07FF,0x0c,0x04,0xa0,0xa0,0xa0,0xa0,0xa0,0x04,0x0c,0x07FF,0x07FF
,0x07FF,0x07FF,0x07FF,0x07FF,0x08,0x00,0x24,0x6d,0x6d,0x00,0x04,0x08,0x08,0x00,0x45,0x60,0x60,0x60,0x60,0x60,0x60,0x60,0x60,0x60,0x60,0x60,0x60,0x60,0x60,0x60,0x60,0x00,0x08,0x07FF,0x07FF,0x07FF,0x07FF,0x07FF,0x07FF,0x07FF,0x0c,0x04,0x00,0x92,0xff,0xff,0xff,0x6d,0x00,0x00,0x04,0x07FF,0x07FF,0x0c,0x28,0x60,0xe0,0xe0,0xe0,0xe0,0xe0,0x60,0x28,0x0c,0x07FF
,0x07FF,0x07FF,0x07FF,0x07FF,0x07FF,0x04,0x6d,0xff,0xff,0x00,0x0c,0x07FF,0x07FF,0x00,0x45,0x60,0x60,0x60,0x60,0x60,0x60,0x60,0x60,0x60,0x60,0x60,0x60,0x60,0x60,0x60,0x60,0x00,0x08,0x07FF,0x07FF,0x07FF,0x07FF,0x07FF,0x07FF,0x07FF,0x07FF,0x0c,0x00,0x00,0xb6,0xff,0xff,0xff,0x24,0x00,0x04,0x11,0x07FF,0x04,0x40,0xe0,0xe0,0xe0,0xe0,0xe0,0xe0,0xe0,0x40,0x04,0x07FF
,0x07FF,0x07FF,0x07FF,0x07FF,0x07FF,0x04,0x6d,0xff,0xff,0x00,0x0c,0x07FF,0x07FF,0x00,0x45,0x60,0x60,0x60,0x60,0x60,0x60,0x60,0x60,0x60,0x60,0x60,0x60,0x60,0x60,0x60,0x60,0x00,0x08,0x07FF,0x07FF,0x07FF,0x07FF,0x07FF,0x07FF,0x07FF,0x07FF,0x07FF,0x11,0x00,0x00,0x6d,0xff,0xff,0xff,0x6d,0x00,0x00,0x07FF,0x04,0x40,0xe0,0xe0,0xe0,0xe0,0xe0,0xe0,0xe0,0x40,0x04,0x07FF
,0x07FF,0x07FF,0x07FF,0x07FF,0x07FF,0x04,0x6d,0xff,0xff,0x00,0x0c,0x07FF,0x07FF,0x00,0x45,0x60,0x60,0x60,0x60,0x60,0x60,0x60,0x60,0x60,0x60,0x60,0x60,0x60,0x60,0x60,0x60,0x00,0x08,0x07FF,0x07FF,0x07FF,0x07FF,0x07FF,0x07FF,0x07FF,0x07FF,0x07FF,0x07FF,0x11,0x00,0x00,0x49,0xff,0xff,0xff,0x92,0x00,0x00,0x00,0x40,0xe0,0xe0,0xe0,0xe0,0xe0,0xe0,0xe0,0x40,0x04,0x07FF
,0x07FF,0x07FF,0x07FF,0x07FF,0x07FF,0x04,0x6d,0xff,0xff,0x00,0x0c,0x07FF,0x07FF,0x00,0x45,0x60,0x60,0x60,0x60,0x60,0x60,0x60,0x60,0x60,0x60,0x60,0x60,0x60,0x60,0x60,0x60,0x00,0x08,0x07FF,0x07FF,0x07FF,0x07FF,0x07FF,0x07FF,0x07FF,0x07FF,0x07FF,0x07FF,0x07FF,0x0c,0x04,0x00,0x6d,0xff,0xff,0xdb,0x92,0x00,0x00,0x40,0xe0,0xe0,0xe0,0xe0,0xe0,0xe0,0xe0,0x40,0x04,0x07FF
,0x07FF,0x07FF,0x07FF,0x07FF,0x07FF,0x04,0x6d,0xff,0xff,0x00,0x0c,0x07FF,0x07FF,0x00,0x45,0x60,0x60,0x60,0x60,0x60,0x60,0x60,0x60,0x60,0x60,0x60,0x60,0x60,0x60,0x60,0x60,0x00,0x08,0x07FF,0x07FF,0x07FF,0x07FF,0x07FF,0x07FF,0x07FF,0x07FF,0x07FF,0x07FF,0x07FF,0x07FF,0x0c,0x04,0x00,0xb6,0xff,0xff,0xff,0x00,0x00,0x40,0xa0,0xe0,0xe0,0xe0,0xe0,0xe0,0xa0,0x44,0x08,0x07FF
,0x07FF,0x07FF,0x07FF,0x07FF,0x07FF,0x04,0x6d,0xff,0xff,0x00,0x0c,0x07FF,0x07FF,0x00,0x45,0x60,0x60,0x60,0x60,0x60,0x60,0x60,0x60,0x60,0x60,0x60,0x60,0x60,0x60,0x60,0x60,0x00,0x08,0x07FF,0x07FF,0x07FF,0x07FF,0x07FF,0x07FF,0x07FF,0x07FF,0x07FF,0x07FF,0x07FF,0x07FF,0x07FF,0x10,0x00,0x00,0x92,0xff,0xff,0x00,0x00,0x00,0x00,0xe0,0xe0,0xe0,0xe0,0xe0,0x00,0x0c,0x07FF,0x07FF
,0x07FF,0x07FF,0x07FF,0x07FF,0x07FF,0x04,0x6d,0xff,0xff,0x00,0x0c,0x07FF,0x07FF,0x00,0x45,0x60,0x60,0x60,0x60,0x60,0x60,0x60,0x60,0x60,0x60,0x60,0x60,0x60,0x60,0x60,0x60,0x00,0x08,0x07FF,0x07FF,0x07FF,0x07FF,0x07FF,0x07FF,0x07FF,0x07FF,0x07FF,0x07FF,0x07FF,0x07FF,0x07FF,0x07FF,0x07FF,0x00,0x00,0x49,0xff,0x00,0x00,0x00,0x00,0x00,0x00,0x00,0x00,0x00,0x11,0x07FF,0x07FF,0x07FF
,0x07FF,0x07FF,0x07FF,0x07FF,0x07FF,0x04,0x6d,0xff,0xff,0x00,0x0c,0x07FF,0x07FF,0x00,0x45,0x60,0x60,0x60,0x60,0x60,0x60,0x60,0x60,0x60,0x60,0x60,0x60,0x60,0x60,0x60,0x60,0x00,0x08,0x07FF,0x07FF,0x07FF,0x07FF,0x07FF,0x07FF,0x07FF,0x07FF,0x07FF,0x07FF,0x07FF,0x07FF,0x07FF,0x07FF,0x07FF,0x10,0x04,0x00,0x49,0x00,0x00,0x04,0x0c,0x0c,0x0c,0x0c,0x0c,0x0c,0x07FF,0x07FF,0x07FF,0x07FF
,0x07FF,0x07FF,0x07FF,0x07FF,0x07FF,0x04,0x6d,0xff,0xff,0x00,0x0c,0x07FF,0x07FF,0x00,0x45,0x60,0x60,0x60,0x60,0x60,0x60,0x60,0x60,0x60,0x60,0x60,0x60,0x60,0x60,0x60,0x60,0x00,0x08,0x07FF,0x07FF,0x07FF,0x07FF,0x07FF,0x07FF,0x07FF,0x07FF,0x07FF,0x07FF,0x07FF,0x07FF,0x07FF,0x07FF,0x07FF,0x07FF,0x0c,0x04,0x00,0x00,0x04,0x0c,0x07FF,0x07FF,0x07FF,0x07FF,0x07FF,0x07FF,0x07FF,0x07FF,0x07FF,0x07FF
,0x07FF,0x07FF,0x07FF,0x07FF,0x07FF,0x04,0x6d,0xff,0xff,0x00,0x08,0x11,0x07FF,0x00,0x45,0x60,0x60,0x60,0x60,0x60,0x60,0x60,0x60,0x60,0x60,0x60,0x60,0x60,0x60,0x60,0x60,0x00,0x08,0x07FF,0x07FF,0x07FF,0x07FF,0x07FF,0x07FF,0x07FF,0x07FF,0x07FF,0x07FF,0x07FF,0x07FF,0x07FF,0x07FF,0x07FF,0x07FF,0x07FF,0x10,0x00,0x00,0x10,0x07FF,0x07FF,0x07FF,0x07FF,0x07FF,0x07FF,0x07FF,0x07FF,0x07FF,0x07FF,0x07FF
,0x07FF,0x07FF,0x07FF,0x07FF,0x07FF,0x04,0x6d,0xff,0xff,0x00,0x00,0x04,0x07FF,0x00,0x45,0x60,0x60,0x60,0x60,0x60,0x60,0x60,0x60,0x60,0x60,0x60,0x60,0x60,0x60,0x60,0x60,0x00,0x08,0x07FF,0x07FF,0x07FF,0x07FF,0x07FF,0x07FF,0x07FF,0x07FF,0x07FF,0x07FF,0x07FF,0x07FF,0x07FF,0x07FF,0x07FF,0x07FF,0x07FF,0x07FF,0x07FF,0x07FF,0x07FF,0x07FF,0x07FF,0x07FF,0x07FF,0x07FF,0x07FF,0x07FF,0x07FF,0x07FF,0x07FF,0x07FF
,0x07FF,0x07FF,0x07FF,0x07FF,0x07FF,0x04,0x00,0x49,0xff,0xdb,0x49,0x04,0x07FF,0x00,0x45,0x60,0x60,0x60,0x60,0x60,0x60,0x60,0x60,0x60,0x60,0x60,0x60,0x60,0x60,0x60,0x60,0x00,0x08,0x07FF,0x07FF,0x07FF,0x07FF,0x07FF,0x07FF,0x07FF,0x07FF,0x07FF,0x07FF,0x07FF,0x07FF,0x07FF,0x07FF,0x07FF,0x07FF,0x07FF,0x07FF,0x07FF,0x07FF,0x07FF,0x07FF,0x07FF,0x07FF,0x07FF,0x07FF,0x07FF,0x07FF,0x07FF,0x07FF,0x07FF,0x07FF
,0x07FF,0x07FF,0x07FF,0x07FF,0x07FF,0x0c,0x04,0x24,0xff,0xff,0x6d,0x00,0x08,0x00,0x45,0x60,0x60,0x60,0x60,0x60,0x60,0x60,0x60,0x60,0x60,0x60,0x60,0x60,0x60,0x60,0x60,0x00,0x08,0x07FF,0x07FF,0x07FF,0x07FF,0x07FF,0x07FF,0x07FF,0x07FF,0x07FF,0x07FF,0x07FF,0x07FF,0x07FF,0x07FF,0x07FF,0x07FF,0x07FF,0x07FF,0x07FF,0x07FF,0x07FF,0x07FF,0x07FF,0x07FF,0x07FF,0x07FF,0x07FF,0x07FF,0x07FF,0x07FF,0x07FF,0x07FF
,0x07FF,0x07FF,0x07FF,0x07FF,0x07FF,0x07FF,0x08,0x24,0xb6,0xff,0x92,0x24,0x00,0x00,0x45,0x60,0x60,0x60,0x60,0x60,0x60,0x60,0x60,0x60,0x60,0x60,0x60,0x60,0x60,0x60,0x60,0x00,0x08,0x07FF,0x07FF,0x07FF,0x07FF,0x07FF,0x07FF,0x07FF,0x07FF,0x07FF,0x07FF,0x07FF,0x07FF,0x07FF,0x07FF,0x07FF,0x07FF,0x07FF,0x07FF,0x07FF,0x07FF,0x07FF,0x07FF,0x07FF,0x07FF,0x07FF,0x07FF,0x07FF,0x07FF,0x07FF,0x07FF,0x07FF,0x07FF
,0x07FF,0x07FF,0x07FF,0x07FF,0x07FF,0x07FF,0x08,0x00,0x00,0xff,0xff,0xb6,0x00,0x00,0x45,0x60,0x60,0x60,0x60,0x60,0x60,0x60,0x60,0x60,0x60,0x60,0x60,0x60,0x60,0x60,0x60,0x00,0x08,0x07FF,0x07FF,0x07FF,0x07FF,0x07FF,0x07FF,0x07FF,0x07FF,0x07FF,0x07FF,0x07FF,0x07FF,0x07FF,0x07FF,0x07FF,0x07FF,0x07FF,0x07FF,0x07FF,0x07FF,0x07FF,0x07FF,0x07FF,0x07FF,0x07FF,0x07FF,0x07FF,0x07FF,0x07FF,0x07FF,0x07FF,0x07FF
,0x07FF,0x07FF,0x07FF,0x07FF,0x07FF,0x07FF,0x07FF,0x10,0x00,0xff,0xff,0xb6,0x00,0x00,0x00,0x00,0x00,0x00,0x00,0x00,0x00,0x00,0x00,0x00,0x00,0x00,0x00,0x00,0x00,0x00,0x00,0x00,0x08,0x07FF,0x07FF,0x07FF,0x07FF,0x07FF,0x07FF,0x07FF,0x07FF,0x07FF,0x07FF,0x07FF,0x07FF,0x07FF,0x07FF,0x07FF,0x07FF,0x07FF,0x07FF,0x07FF,0x07FF,0x07FF,0x07FF,0x07FF,0x07FF,0x07FF,0x07FF,0x07FF,0x07FF,0x07FF,0x07FF,0x07FF,0x07FF
,0x07FF,0x07FF,0x07FF,0x07FF,0x07FF,0x07FF,0x07FF,0x07FF,0x0c,0x49,0xb6,0xff,0xb6,0x00,0x00,0x00,0x00,0x00,0x00,0x00,0x00,0x00,0x00,0x00,0x00,0x00,0x00,0x00,0x00,0x00,0x00,0x00,0x08,0x07FF,0x07FF,0x07FF,0x07FF,0x07FF,0x07FF,0x07FF,0x07FF,0x07FF,0x07FF,0x07FF,0x07FF,0x07FF,0x07FF,0x07FF,0x07FF,0x07FF,0x07FF,0x07FF,0x07FF,0x07FF,0x07FF,0x07FF,0x07FF,0x07FF,0x07FF,0x07FF,0x07FF,0x07FF,0x07FF,0x07FF,0x07FF
,0x07FF,0x07FF,0x07FF,0x07FF,0x07FF,0x07FF,0x07FF,0x07FF,0x07FF,0x00,0x49,0xb6,0xff,0x00,0x00,0x00,0x00,0x00,0x00,0x00,0x00,0x00,0x00,0x00,0x00,0x00,0x00,0x00,0x00,0x00,0x00,0x00,0x08,0x07FF,0x07FF,0x07FF,0x07FF,0x07FF,0x07FF,0x07FF,0x07FF,0x07FF,0x07FF,0x07FF,0x07FF,0x07FF,0x07FF,0x07FF,0x07FF,0x07FF,0x07FF,0x07FF,0x07FF,0x07FF,0x07FF,0x07FF,0x07FF,0x07FF,0x07FF,0x07FF,0x07FF,0x07FF,0x07FF,0x07FF,0x07FF
,0x07FF,0x07FF,0x07FF,0x07FF,0x07FF,0x07FF,0x07FF,0x07FF,0x07FF,0x04,0x00,0x49,0xdb,0x00,0x00,0x00,0x00,0x00,0x00,0x00,0x00,0x00,0x00,0x00,0x00,0x00,0x00,0x00,0x00,0x00,0x00,0x00,0x08,0x07FF,0x07FF,0x07FF,0x07FF,0x07FF,0x07FF,0x07FF,0x07FF,0x07FF,0x07FF,0x07FF,0x07FF,0x07FF,0x07FF,0x07FF,0x07FF,0x07FF,0x07FF,0x07FF,0x07FF,0x07FF,0x07FF,0x07FF,0x07FF,0x07FF,0x07FF,0x07FF,0x07FF,0x07FF,0x07FF,0x07FF,0x07FF
,0x07FF,0x07FF,0x07FF,0x07FF,0x07FF,0x07FF,0x07FF,0x07FF,0x07FF,0x07FF,0x08,0x00,0x00,0x00,0x00,0x00,0x00,0x00,0x00,0x00,0x00,0x00,0x00,0x00,0x00,0x00,0x00,0x00,0x00,0x00,0x00,0x00,0x08,0x07FF,0x07FF,0x07FF,0x07FF,0x07FF,0x07FF,0x07FF,0x07FF,0x07FF,0x07FF,0x07FF,0x07FF,0x07FF,0x07FF,0x07FF,0x07FF,0x07FF,0x07FF,0x07FF,0x07FF,0x07FF,0x07FF,0x07FF,0x07FF,0x07FF,0x07FF,0x07FF,0x07FF,0x07FF,0x07FF,0x07FF,0x07FF
,0x07FF,0x07FF,0x07FF,0x07FF,0x07FF,0x07FF,0x07FF,0x07FF,0x07FF,0x07FF,0x15,0x11,0x11,0x00,0x00,0x00,0x00,0x00,0x00,0x00,0x00,0x00,0x00,0x00,0x00,0x00,0x00,0x00,0x00,0x00,0x00,0x00,0x08,0x07FF,0x07FF,0x07FF,0x07FF,0x07FF,0x07FF,0x07FF,0x07FF,0x07FF,0x07FF,0x07FF,0x07FF,0x07FF,0x07FF,0x07FF,0x07FF,0x07FF,0x07FF,0x07FF,0x07FF,0x07FF,0x07FF,0x07FF,0x07FF,0x07FF,0x07FF,0x07FF,0x07FF,0x07FF,0x07FF,0x07FF,0x07FF
,0x07FF,0x07FF,0x07FF,0x07FF,0x07FF,0x07FF,0x07FF,0x07FF,0x07FF,0x07FF,0x07FF,0x07FF,0x07FF,0x00,0x00,0x00,0x00,0x00,0x00,0x00,0x00,0x00,0x00,0x00,0x00,0x00,0x00,0x00,0x00,0x00,0x00,0x00,0x08,0x07FF,0x07FF,0x07FF,0x07FF,0x07FF,0x07FF,0x07FF,0x07FF,0x07FF,0x07FF,0x07FF,0x07FF,0x07FF,0x07FF,0x07FF,0x07FF,0x07FF,0x07FF,0x07FF,0x07FF,0x07FF,0x07FF,0x07FF,0x07FF,0x07FF,0x07FF,0x07FF,0x07FF,0x07FF,0x07FF,0x07FF,0x07FF
,0x07FF,0x07FF,0x07FF,0x07FF,0x07FF,0x07FF,0x07FF,0x07FF,0x07FF,0x07FF,0x07FF,0x07FF,0x07FF,0x00,0x00,0x00,0x00,0x00,0x00,0x00,0x00,0x00,0x00,0x00,0x00,0x00,0x00,0x00,0x00,0x00,0x00,0x00,0x08,0x07FF,0x07FF,0x07FF,0x07FF,0x07FF,0x07FF,0x07FF,0x07FF,0x07FF,0x07FF,0x07FF,0x07FF,0x07FF,0x07FF,0x07FF,0x07FF,0x07FF,0x07FF,0x07FF,0x07FF,0x07FF,0x07FF,0x07FF,0x07FF,0x07FF,0x07FF,0x07FF,0x07FF,0x07FF,0x07FF,0x07FF,0x07FF
,0x07FF,0x07FF,0x07FF,0x07FF,0x07FF,0x07FF,0x07FF,0x07FF,0x07FF,0x07FF,0x07FF,0x07FF,0x07FF,0x00,0x00,0x00,0x00,0x00,0x00,0x00,0x00,0x00,0x00,0x00,0x00,0x00,0x00,0x00,0x00,0x00,0x00,0x00,0x08,0x07FF,0x07FF,0x07FF,0x07FF,0x07FF,0x07FF,0x07FF,0x07FF,0x07FF,0x07FF,0x07FF,0x07FF,0x07FF,0x07FF,0x07FF,0x07FF,0x07FF,0x07FF,0x07FF,0x07FF,0x07FF,0x07FF,0x07FF,0x07FF,0x07FF,0x07FF,0x07FF,0x07FF,0x07FF,0x07FF,0x07FF,0x07FF
,0x07FF,0x07FF,0x07FF,0x07FF,0x07FF,0x07FF,0x07FF,0x07FF,0x07FF,0x07FF,0x07FF,0x07FF,0x07FF,0x00,0x00,0x00,0x00,0x00,0x00,0x00,0x00,0x00,0x00,0x00,0x00,0x00,0x00,0x00,0x00,0x00,0x00,0x00,0x08,0x07FF,0x07FF,0x07FF,0x07FF,0x07FF,0x07FF,0x07FF,0x07FF,0x07FF,0x07FF,0x07FF,0x07FF,0x07FF,0x07FF,0x07FF,0x07FF,0x07FF,0x07FF,0x07FF,0x07FF,0x07FF,0x07FF,0x07FF,0x07FF,0x07FF,0x07FF,0x07FF,0x07FF,0x07FF,0x07FF,0x07FF,0x07FF
,0x07FF,0x07FF,0x07FF,0x07FF,0x07FF,0x07FF,0x07FF,0x07FF,0x07FF,0x07FF,0x07FF,0x07FF,0x07FF,0x00,0x00,0x00,0x00,0x00,0x00,0x00,0x00,0x00,0x00,0x00,0x00,0x00,0x00,0x00,0x00,0x00,0x00,0x00,0x08,0x07FF,0x07FF,0x07FF,0x07FF,0x07FF,0x07FF,0x07FF,0x07FF,0x07FF,0x07FF,0x07FF,0x07FF,0x07FF,0x07FF,0x07FF,0x07FF,0x07FF,0x07FF,0x07FF,0x07FF,0x07FF,0x07FF,0x07FF,0x07FF,0x07FF,0x07FF,0x07FF,0x07FF,0x07FF,0x07FF,0x07FF,0x07FF
,0x07FF,0x07FF,0x07FF,0x07FF,0x07FF,0x07FF,0x07FF,0x07FF,0x07FF,0x07FF,0x07FF,0x07FF,0x07FF,0x00,0x00,0x00,0x00,0x00,0x00,0x00,0x00,0x00,0x00,0x00,0x00,0x00,0x00,0x00,0x00,0x00,0x00,0x00,0x08,0x07FF,0x07FF,0x07FF,0x07FF,0x07FF,0x07FF,0x07FF,0x07FF,0x07FF,0x07FF,0x07FF,0x07FF,0x07FF,0x07FF,0x07FF,0x07FF,0x07FF,0x07FF,0x07FF,0x07FF,0x07FF,0x07FF,0x07FF,0x07FF,0x07FF,0x07FF,0x07FF,0x07FF,0x07FF,0x07FF,0x07FF,0x07FF
,0x07FF,0x07FF,0x07FF,0x07FF,0x07FF,0x07FF,0x07FF,0x07FF,0x07FF,0x07FF,0x07FF,0x07FF,0x07FF,0x00,0x00,0x00,0x00,0x00,0x00,0x00,0x00,0x00,0x00,0x00,0x00,0x00,0x00,0x00,0x00,0x00,0x00,0x00,0x08,0x07FF,0x07FF,0x07FF,0x07FF,0x07FF,0x07FF,0x07FF,0x07FF,0x07FF,0x07FF,0x07FF,0x07FF,0x07FF,0x07FF,0x07FF,0x07FF,0x07FF,0x07FF,0x07FF,0x07FF,0x07FF,0x07FF,0x07FF,0x07FF,0x07FF,0x07FF,0x07FF,0x07FF,0x07FF,0x07FF,0x07FF,0x07FF
,0x07FF,0x07FF,0x07FF,0x07FF,0x07FF,0x07FF,0x07FF,0x07FF,0x07FF,0x07FF,0x07FF,0x07FF,0x07FF,0x00,0x00,0x00,0x00,0x00,0x00,0x00,0x00,0x00,0x00,0x00,0x00,0x00,0x00,0x00,0x00,0x00,0x00,0x00,0x08,0x07FF,0x07FF,0x07FF,0x07FF,0x07FF,0x07FF,0x07FF,0x07FF,0x07FF,0x07FF,0x07FF,0x07FF,0x07FF,0x07FF,0x07FF,0x07FF,0x07FF,0x07FF,0x07FF,0x07FF,0x07FF,0x07FF,0x07FF,0x07FF,0x07FF,0x07FF,0x07FF,0x07FF,0x07FF,0x07FF,0x07FF,0x07FF
,0x07FF,0x07FF,0x07FF,0x07FF,0x07FF,0x07FF,0x07FF,0x07FF,0x07FF,0x07FF,0x07FF,0x07FF,0x07FF,0x00,0x00,0x00,0x00,0x00,0x00,0x00,0x00,0x00,0x00,0x00,0x00,0x00,0x00,0x00,0x00,0x00,0x00,0x00,0x08,0x07FF,0x07FF,0x07FF,0x07FF,0x07FF,0x07FF,0x07FF,0x07FF,0x07FF,0x07FF,0x07FF,0x07FF,0x07FF,0x07FF,0x07FF,0x07FF,0x07FF,0x07FF,0x07FF,0x07FF,0x07FF,0x07FF,0x07FF,0x07FF,0x07FF,0x07FF,0x07FF,0x07FF,0x07FF,0x07FF,0x07FF,0x07FF
,0x07FF,0x07FF,0x07FF,0x07FF,0x07FF,0x07FF,0x07FF,0x07FF,0x07FF,0x07FF,0x07FF,0x07FF,0x07FF,0x00,0x00,0x00,0x00,0x00,0x00,0x00,0x00,0x00,0x00,0x00,0x00,0x00,0x00,0x00,0x00,0x00,0x00,0x00,0x08,0x07FF,0x07FF,0x07FF,0x07FF,0x07FF,0x07FF,0x07FF,0x07FF,0x07FF,0x07FF,0x07FF,0x07FF,0x07FF,0x07FF,0x07FF,0x07FF,0x07FF,0x07FF,0x07FF,0x07FF,0x07FF,0x07FF,0x07FF,0x07FF,0x07FF,0x07FF,0x07FF,0x07FF,0x07FF,0x07FF,0x07FF,0x07FF
,0x07FF,0x07FF,0x07FF,0x07FF,0x07FF,0x07FF,0x07FF,0x07FF,0x07FF,0x07FF,0x07FF,0x07FF,0x07FF,0x00,0x00,0x00,0x00,0x00,0x00,0x00,0x00,0x00,0x00,0x00,0x00,0x00,0x00,0x00,0x00,0x00,0x00,0x00,0x08,0x07FF,0x07FF,0x07FF,0x07FF,0x07FF,0x07FF,0x07FF,0x07FF,0x07FF,0x07FF,0x07FF,0x07FF,0x07FF,0x07FF,0x07FF,0x07FF,0x07FF,0x07FF,0x07FF,0x07FF,0x07FF,0x07FF,0x07FF,0x07FF,0x07FF,0x07FF,0x07FF,0x07FF,0x07FF,0x07FF,0x07FF,0x07FF
,0x07FF,0x07FF,0x07FF,0x07FF,0x07FF,0x07FF,0x07FF,0x07FF,0x07FF,0x07FF,0x07FF,0x07FF,0x07FF,0x00,0x00,0x00,0x00,0x00,0x00,0x00,0x00,0x00,0x00,0x00,0x00,0x00,0x00,0x00,0x00,0x00,0x00,0x00,0x08,0x07FF,0x07FF,0x07FF,0x07FF,0x07FF,0x07FF,0x07FF,0x07FF,0x07FF,0x07FF,0x07FF,0x07FF,0x07FF,0x07FF,0x07FF,0x07FF,0x07FF,0x07FF,0x07FF,0x07FF,0x07FF,0x07FF,0x07FF,0x07FF,0x07FF,0x07FF,0x07FF,0x07FF,0x07FF,0x07FF,0x07FF,0x07FF
,0x07FF,0x07FF,0x07FF,0x07FF,0x07FF,0x07FF,0x07FF,0x07FF,0x07FF,0x07FF,0x07FF,0x07FF,0x07FF,0x00,0x00,0x00,0x00,0x00,0x00,0x00,0x00,0x00,0x00,0x00,0x00,0x00,0x00,0x00,0x00,0x00,0x00,0x00,0x08,0x07FF,0x07FF,0x07FF,0x07FF,0x07FF,0x07FF,0x07FF,0x07FF,0x07FF,0x07FF,0x07FF,0x07FF,0x07FF,0x07FF,0x07FF,0x07FF,0x07FF,0x07FF,0x07FF,0x07FF,0x07FF,0x07FF,0x07FF,0x07FF,0x07FF,0x07FF,0x07FF,0x07FF,0x07FF,0x07FF,0x07FF,0x07FF
,0x07FF,0x07FF,0x07FF,0x07FF,0x07FF,0x07FF,0x07FF,0x07FF,0x07FF,0x07FF,0x07FF,0x07FF,0x07FF,0x0c,0x0c,0x08,0x00,0xb6,0xb6,0x49,0x00,0x0c,0x0c,0x0c,0x0c,0x0c,0x00,0x6d,0xb6,0xb6,0x00,0x0c,0x11,0x07FF,0x07FF,0x07FF,0x07FF,0x07FF,0x07FF,0x07FF,0x07FF,0x07FF,0x07FF,0x07FF,0x07FF,0x07FF,0x07FF,0x07FF,0x07FF,0x07FF,0x07FF,0x07FF,0x07FF,0x07FF,0x07FF,0x07FF,0x07FF,0x07FF,0x07FF,0x07FF,0x07FF,0x07FF,0x07FF,0x07FF,0x07FF
,0x07FF,0x07FF,0x07FF,0x07FF,0x07FF,0x07FF,0x07FF,0x07FF,0x07FF,0x07FF,0x07FF,0x07FF,0x07FF,0x07FF,0x07FF,0x0c,0x00,0xff,0xff,0x6d,0x04,0x07FF,0x07FF,0x07FF,0x07FF,0x07FF,0x00,0xb6,0xff,0xff,0x00,0x10,0x07FF,0x07FF,0x07FF,0x07FF,0x07FF,0x07FF,0x07FF,0x07FF,0x07FF,0x07FF,0x07FF,0x07FF,0x07FF,0x07FF,0x07FF,0x07FF,0x07FF,0x07FF,0x07FF,0x07FF,0x07FF,0x07FF,0x07FF,0x07FF,0x07FF,0x07FF,0x07FF,0x07FF,0x07FF,0x07FF,0x07FF,0x07FF,0x07FF
,0x07FF,0x07FF,0x07FF,0x07FF,0x07FF,0x07FF,0x07FF,0x07FF,0x07FF,0x07FF,0x07FF,0x07FF,0x07FF,0x07FF,0x07FF,0x0c,0x00,0xff,0xff,0x6d,0x04,0x07FF,0x07FF,0x07FF,0x07FF,0x07FF,0x00,0xb6,0xff,0xff,0x00,0x10,0x07FF,0x07FF,0x07FF,0x07FF,0x07FF,0x07FF,0x07FF,0x07FF,0x07FF,0x07FF,0x07FF,0x07FF,0x07FF,0x07FF,0x07FF,0x07FF,0x07FF,0x07FF,0x07FF,0x07FF,0x07FF,0x07FF,0x07FF,0x07FF,0x07FF,0x07FF,0x07FF,0x07FF,0x07FF,0x07FF,0x07FF,0x07FF,0x07FF
,0x07FF,0x07FF,0x07FF,0x07FF,0x07FF,0x07FF,0x07FF,0x07FF,0x07FF,0x07FF,0x07FF,0x07FF,0x07FF,0x07FF,0x07FF,0x0c,0x00,0xff,0xff,0x6d,0x04,0x07FF,0x07FF,0x07FF,0x07FF,0x07FF,0x00,0xb6,0xff,0xff,0x00,0x10,0x07FF,0x07FF,0x07FF,0x07FF,0x07FF,0x07FF,0x07FF,0x07FF,0x07FF,0x07FF,0x07FF,0x07FF,0x07FF,0x07FF,0x07FF,0x07FF,0x07FF,0x07FF,0x07FF,0x07FF,0x07FF,0x07FF,0x07FF,0x07FF,0x07FF,0x07FF,0x07FF,0x07FF,0x07FF,0x07FF,0x07FF,0x07FF,0x07FF
,0x07FF,0x07FF,0x07FF,0x07FF,0x07FF,0x07FF,0x07FF,0x07FF,0x07FF,0x07FF,0x07FF,0x07FF,0x07FF,0x07FF,0x07FF,0x0c,0x00,0xff,0xff,0x6d,0x04,0x07FF,0x07FF,0x07FF,0x07FF,0x07FF,0x00,0xb6,0xff,0xff,0x00,0x10,0x07FF,0x07FF,0x07FF,0x07FF,0x07FF,0x07FF,0x07FF,0x07FF,0x07FF,0x07FF,0x07FF,0x07FF,0x07FF,0x07FF,0x07FF,0x07FF,0x07FF,0x07FF,0x07FF,0x07FF,0x07FF,0x07FF,0x07FF,0x07FF,0x07FF,0x07FF,0x07FF,0x07FF,0x07FF,0x07FF,0x07FF,0x07FF,0x07FF
,0x07FF,0x07FF,0x07FF,0x07FF,0x07FF,0x07FF,0x07FF,0x07FF,0x07FF,0x07FF,0x07FF,0x07FF,0x07FF,0x07FF,0x07FF,0x0c,0x00,0xff,0xff,0x6d,0x04,0x07FF,0x07FF,0x07FF,0x07FF,0x07FF,0x00,0xb6,0xff,0xff,0x00,0x10,0x07FF,0x07FF,0x07FF,0x07FF,0x07FF,0x07FF,0x07FF,0x07FF,0x07FF,0x07FF,0x07FF,0x07FF,0x07FF,0x07FF,0x07FF,0x07FF,0x07FF,0x07FF,0x07FF,0x07FF,0x07FF,0x07FF,0x07FF,0x07FF,0x07FF,0x07FF,0x07FF,0x07FF,0x07FF,0x07FF,0x07FF,0x07FF,0x07FF
,0x07FF,0x07FF,0x07FF,0x07FF,0x07FF,0x07FF,0x07FF,0x07FF,0x07FF,0x07FF,0x07FF,0x07FF,0x07FF,0x07FF,0x07FF,0x0c,0x00,0xff,0xff,0x6d,0x04,0x07FF,0x07FF,0x07FF,0x07FF,0x07FF,0x00,0xb6,0xff,0xff,0x00,0x10,0x07FF,0x07FF,0x07FF,0x07FF,0x07FF,0x07FF,0x07FF,0x07FF,0x07FF,0x07FF,0x07FF,0x07FF,0x07FF,0x07FF,0x07FF,0x07FF,0x07FF,0x07FF,0x07FF,0x07FF,0x07FF,0x07FF,0x07FF,0x07FF,0x07FF,0x07FF,0x07FF,0x07FF,0x07FF,0x07FF,0x07FF,0x07FF,0x07FF
,0x07FF,0x07FF,0x07FF,0x07FF,0x07FF,0x07FF,0x07FF,0x07FF,0x07FF,0x07FF,0x07FF,0x07FF,0x07FF,0x07FF,0x07FF,0x0c,0x00,0xff,0xff,0x6d,0x04,0x07FF,0x07FF,0x07FF,0x07FF,0x07FF,0x00,0xb6,0xff,0xff,0x00,0x10,0x07FF,0x07FF,0x07FF,0x07FF,0x07FF,0x07FF,0x07FF,0x07FF,0x07FF,0x07FF,0x07FF,0x07FF,0x07FF,0x07FF,0x07FF,0x07FF,0x07FF,0x07FF,0x07FF,0x07FF,0x07FF,0x07FF,0x07FF,0x07FF,0x07FF,0x07FF,0x07FF,0x07FF,0x07FF,0x07FF,0x07FF,0x07FF,0x07FF
,0x07FF,0x07FF,0x07FF,0x07FF,0x07FF,0x07FF,0x07FF,0x07FF,0x07FF,0x07FF,0x07FF,0x07FF,0x07FF,0x07FF,0x07FF,0x0c,0x00,0xff,0xff,0x6d,0x04,0x07FF,0x07FF,0x07FF,0x07FF,0x07FF,0x00,0xb6,0xff,0xff,0x00,0x10,0x07FF,0x07FF,0x07FF,0x07FF,0x07FF,0x07FF,0x07FF,0x07FF,0x07FF,0x07FF,0x07FF,0x07FF,0x07FF,0x07FF,0x07FF,0x07FF,0x07FF,0x07FF,0x07FF,0x07FF,0x07FF,0x07FF,0x07FF,0x07FF,0x07FF,0x07FF,0x07FF,0x07FF,0x07FF,0x07FF,0x07FF,0x07FF,0x07FF
,0x07FF,0x07FF,0x07FF,0x07FF,0x07FF,0x07FF,0x07FF,0x07FF,0x07FF,0x07FF,0x07FF,0x07FF,0x07FF,0x07FF,0x07FF,0x0c,0x00,0xff,0xff,0x6d,0x04,0x07FF,0x07FF,0x07FF,0x07FF,0x07FF,0x00,0xb6,0xff,0xff,0x00,0x10,0x07FF,0x07FF,0x07FF,0x07FF,0x07FF,0x07FF,0x07FF,0x07FF,0x07FF,0x07FF,0x07FF,0x07FF,0x07FF,0x07FF,0x07FF,0x07FF,0x07FF,0x07FF,0x07FF,0x07FF,0x07FF,0x07FF,0x07FF,0x07FF,0x07FF,0x07FF,0x07FF,0x07FF,0x07FF,0x07FF,0x07FF,0x07FF,0x07FF
,0x07FF,0x07FF,0x07FF,0x07FF,0x07FF,0x07FF,0x07FF,0x07FF,0x07FF,0x07FF,0x07FF,0x07FF,0x07FF,0x07FF,0x07FF,0x0c,0x00,0xff,0xff,0x6d,0x04,0x07FF,0x07FF,0x07FF,0x07FF,0x07FF,0x00,0xb6,0xff,0xff,0x00,0x10,0x07FF,0x07FF,0x07FF,0x07FF,0x07FF,0x07FF,0x07FF,0x07FF,0x07FF,0x07FF,0x07FF,0x07FF,0x07FF,0x07FF,0x07FF,0x07FF,0x07FF,0x07FF,0x07FF,0x07FF,0x07FF,0x07FF,0x07FF,0x07FF,0x07FF,0x07FF,0x07FF,0x07FF,0x07FF,0x07FF,0x07FF,0x07FF,0x07FF
,0x07FF,0x07FF,0x07FF,0x07FF,0x07FF,0x07FF,0x07FF,0x07FF,0x07FF,0x07FF,0x07FF,0x07FF,0x07FF,0x07FF,0x11,0x08,0x00,0xdb,0xdb,0x6d,0x00,0x11,0x07FF,0x07FF,0x07FF,0x11,0x00,0x92,0xdb,0xdb,0x00,0x0c,0x11,0x11,0x11,0x11,0x11,0x11,0x07FF,0x07FF,0x07FF,0x07FF,0x07FF,0x07FF,0x07FF,0x07FF,0x07FF,0x07FF,0x07FF,0x07FF,0x07FF,0x07FF,0x07FF,0x07FF,0x07FF,0x07FF,0x07FF,0x07FF,0x07FF,0x07FF,0x07FF,0x07FF,0x07FF,0x07FF,0x07FF
,0x07FF,0x07FF,0x07FF,0x07FF,0x07FF,0x07FF,0x07FF,0x07FF,0x07FF,0x07FF,0x07FF,0x07FF,0x07FF,0x07FF,0x04,0x00,0x00,0x00,0x00,0x00,0x00,0x00,0x11,0x07FF,0x0c,0x00,0x00,0x00,0x00,0x00,0x00,0x00,0x00,0x00,0x00,0x00,0x00,0x04,0x07FF,0x07FF,0x07FF,0x07FF,0x07FF,0x07FF,0x07FF,0x07FF,0x07FF,0x07FF,0x07FF,0x07FF,0x07FF,0x07FF,0x07FF,0x07FF,0x07FF,0x07FF,0x07FF,0x07FF,0x07FF,0x07FF,0x07FF,0x07FF,0x07FF,0x07FF,0x07FF
,0x07FF,0x07FF,0x07FF,0x07FF,0x07FF,0x07FF,0x07FF,0x07FF,0x07FF,0x07FF,0x07FF,0x07FF,0x07FF,0x07FF,0x04,0x20,0x88,0x88,0x88,0x88,0x64,0x00,0x11,0x07FF,0x0c,0x00,0x88,0x88,0x88,0x88,0x88,0x88,0x88,0x88,0x88,0x88,0x20,0x04,0x07FF,0x07FF,0x07FF,0x07FF,0x07FF,0x07FF,0x07FF,0x07FF,0x07FF,0x07FF,0x07FF,0x07FF,0x07FF,0x07FF,0x07FF,0x07FF,0x07FF,0x07FF,0x07FF,0x07FF,0x07FF,0x07FF,0x07FF,0x07FF,0x07FF,0x07FF,0x07FF
,0x07FF,0x07FF,0x07FF,0x07FF,0x07FF,0x07FF,0x07FF,0x07FF,0x07FF,0x07FF,0x07FF,0x07FF,0x07FF,0x07FF,0x04,0x24,0x88,0x88,0x88,0x88,0x68,0x00,0x11,0x07FF,0x0c,0x00,0x88,0x88,0x88,0x88,0x88,0x88,0x88,0x88,0x88,0x88,0x24,0x04,0x07FF,0x07FF,0x07FF,0x07FF,0x07FF,0x07FF,0x07FF,0x07FF,0x07FF,0x07FF,0x07FF,0x07FF,0x07FF,0x07FF,0x07FF,0x07FF,0x07FF,0x07FF,0x07FF,0x07FF,0x07FF,0x07FF,0x07FF,0x07FF,0x07FF,0x07FF,0x07FF
,0x07FF,0x07FF,0x07FF,0x07FF,0x07FF,0x07FF,0x07FF,0x07FF,0x07FF,0x07FF,0x07FF,0x07FF,0x07FF,0x07FF,0x04,0x20,0x68,0x68,0x68,0x68,0x44,0x00,0x11,0x07FF,0x0c,0x00,0x68,0x68,0x68,0x68,0x68,0x68,0x68,0x68,0x68,0x68,0x20,0x04,0x07FF,0x07FF,0x07FF,0x07FF,0x07FF,0x07FF,0x07FF,0x07FF,0x07FF,0x07FF,0x07FF,0x07FF,0x07FF,0x07FF,0x07FF,0x07FF,0x07FF,0x07FF,0x07FF,0x07FF,0x07FF,0x07FF,0x07FF,0x07FF,0x07FF,0x07FF,0x07FF
,0x07FF,0x07FF,0x07FF,0x07FF,0x07FF,0x07FF,0x07FF,0x07FF,0x07FF,0x07FF,0x07FF,0x07FF,0x07FF,0x07FF,0x04,0x00,0x00,0x00,0x00,0x00,0x00,0x00,0x11,0x07FF,0x0c,0x00,0x00,0x00,0x00,0x00,0x00,0x00,0x00,0x00,0x00,0x00,0x00,0x04,0x07FF,0x07FF,0x07FF,0x07FF,0x07FF,0x07FF,0x07FF,0x07FF,0x07FF,0x07FF,0x07FF,0x07FF,0x07FF,0x07FF,0x07FF,0x07FF,0x07FF,0x07FF,0x07FF,0x07FF,0x07FF,0x07FF,0x07FF,0x07FF,0x07FF,0x07FF,0x07FF

};

/* USER CODE END PV */

void SystemClock_Config(void);

/* USER CODE BEGIN 0 */

//float get_temp(void) {
//    uint8_t data[3];
//    uint16_t raw;

//    uint16_t devAddr = (0x5A << 1);

//    HAL_I2C_Mem_Read(&hi2c3, devAddr, 0x06, 1, data, 3, HAL_MAX_DELAY);

//    raw = data[0] | (data[1] << 8);

//    float temp = (raw * 0.02f) - 273.15f;

//    return temp;
//}

void get_temp(float *pixels){
  HAL_StatusTypeDef status;

  uint8_t raw[128];

  status = HAL_I2C_Mem_Read(&hi2c1, AMG8833_ADDR, 0x80, I2C_MEMADD_SIZE_8BIT, raw, 128, 100);

    for(int i = 0; i < 64; i++)
    {
        uint16_t rawValue;
        int16_t signedValue;

        rawValue = raw[i * 2] | (raw[i * 2 + 1] << 8);

        // 12-bit signed conversion
        if(rawValue & 0x800)
        {
            signedValue = rawValue - 4096;
        }
        else
        {
            signedValue = rawValue;
        }

        pixels[i] = signedValue * 0.25f;
    }

}

uint16_t get_color_temp(float temp){
  if (temp < 21) return ILI9341_BLUE;
  if (temp < 22.5) return ILI9341_CYAN;
  if (temp < 23.5) return ILI9341_YELLOW;
  if (temp < 25) return ILI9341_MAGENTA;
  return ILI9341_RED;
}

void draw_sensor_data(float* pixels){
  int pixel_size = 30;

  for (int i = 0; i < 8; i++){
    for (int j = 0; j < 8; j++){
      int index = (i*8) + j;

      float current_temp = pixels[index];

      uint16_t pixel_color = get_color_temp(current_temp);

      uint16_t start_x = j*pixel_size;
      uint16_t start_y = i*pixel_size;

      ILI9341_FillRectangle(start_x, start_y, pixel_size, pixel_size, pixel_color);

    }

  }

}
void draw_player(int side_flag) {
  int x;
  if (side_flag == 0) {
    ILI9341_DrawImage(120, 5, 65, 90, image1);
    ILI9341_FillRectangle(50, 5, 65, 90, ILI9341_GREEN);
  } else {
    ILI9341_FillRectangle(120, 5, 65, 90, ILI9341_GREEN);
    ILI9341_DrawImage(50, 5, 65, 90, image2);
  }
}

void draw_table() {
  ILI9341_FillRectangle(60, 100, 120, 200, ILI9341_BLUE);
  ILI9341_FillRectangle(60, 190, 120, 10, ILI9341_WHITE);
}

void draw_img(int side_flag) {
  draw_player(side_flag);
}

void vApplicationTickHook(void) {
  // printf("TICK!\n");
}

void vApplicationStackOverflowHook(TaskHandle_t xTask, char *pcTaskName) {
  printf("STACK OVERFLOW DETECTED, task: %s\n", pcTaskName);
  while (1) {}
}

void vApplicationMallocFailedHook(void) {
  printf("MALLOC FAILED!\n");
  while (1) {}
}

void task_a(void *params) {
  while (1) {
    printf("--- task_a ---\n");
    vTaskDelay(pdMS_TO_TICKS(3000)); // Block
  }
}
void task_b(void *params) {
  while (1) {
    printf("--- task_b ---\n");
    vTaskDelay(pdMS_TO_TICKS(1000)); // Block
  }
}

void vAutoModeTask(void *params) {

    while (1) {

        if (!auto_mode) {
            vTaskDelay(pdMS_TO_TICKS(100));
            continue;
        }

        HAL_UART_Transmit(
            &huart1,
            (uint8_t*)"SPIN:900:750\n",
            strlen("SPIN:900:750\n"),
            100
        );

        vTaskDelay(pdMS_TO_TICKS(500));

        if(!auto_mode) continue;

        HAL_UART_Transmit(
            &huart1,
            (uint8_t*)"AIM:1750\n",
            strlen("AIM:1700\n"),
            100
        );

        vTaskDelay(pdMS_TO_TICKS(3000));

        if(!auto_mode) continue;

        HAL_UART_Transmit(
            &huart1,
            (uint8_t*)"SHOOT\n",
            strlen("SHOOT\n"),
            100
        );

        vTaskDelay(pdMS_TO_TICKS(2000));

        if(!auto_mode) continue;

        HAL_UART_Transmit(
            &huart1,
            (uint8_t*)"AIM:1600\n",
            strlen("AIM:1600\n"),
            100
        );

        vTaskDelay(pdMS_TO_TICKS(3000));

        if(!auto_mode) continue;

        HAL_UART_Transmit(
            &huart1,
            (uint8_t*)"SHOOT\n",
            strlen("SHOOT\n"),
            100
        );

        vTaskDelay(pdMS_TO_TICKS(2000));

        if(!auto_mode) continue;

        HAL_UART_Transmit(
            &huart1,
            (uint8_t*)"AIM:1450\n",
            strlen("AIM:1450\n"),
            100
        );

        vTaskDelay(pdMS_TO_TICKS(3000));

        if(!auto_mode) continue;

        HAL_UART_Transmit(
            &huart1,
            (uint8_t*)"SHOOT\n",
            strlen("SHOOT\n"),
            100
        );

        vTaskDelay(pdMS_TO_TICKS(2000));
    }
}

void vThermalDataTask(void *params) {

    float pixels[64];

    float sum_right;
    float sum_left;

    int side_flag = 0;

    int shoot_timer = 0;
    int telemetry_timer = 0;

    while(1){

        get_temp(pixels);

        // =========================
        // SUM LEFT / RIGHT
        // =========================

        sum_left = 0.0f;
        sum_right = 0.0f;

        for(int y = 0; y < 8; y++) {

            for(int x = 0; x < 4; x++) {

                sum_left += pixels[x + 8*y];
            }

            for(int x = 4; x < 8; x++) {

                sum_right += pixels[x + 8*y];
            }
        }

        side_flag =
            (sum_left > sum_right) ? 0 : 1;

        if (thermal_mode) {
          if (side_flag) {
            HAL_UART_Transmit(
            &huart1,
            (uint8_t*)"AIM:1750\n",
            strlen("AIM:1700\n"),
            100);

            vTaskDelay(pdMS_TO_TICKS(3000));

            HAL_UART_Transmit(
            &huart1,
            (uint8_t*)"SHOOT\n",
            strlen("SHOOT\n"),
            100);

          } else {
            HAL_UART_Transmit(
            &huart1,
            (uint8_t*)"AIM:1450\n",
            strlen("AIM:1700\n"),
            100);

            vTaskDelay(pdMS_TO_TICKS(3000));

            HAL_UART_Transmit(
            &huart1,
            (uint8_t*)"SHOOT\n",
            strlen("SHOOT\n"),
            100);
          }
        }

        // =========================
        // AUTO MODE
        // =========================

        //if(auto_mode) {

        //    char uart_msg[32];

        //    // spelare vänster
        //    if(side_flag == 0) {

        //        aim_value = 1700;

        //    } else {

        //        aim_value = 1500;
        //    }

        //    // AIM
        //    sprintf(
        //        uart_msg,
        //        "AIM:%d\n",
        //        aim_value
        //    );

        //    HAL_UART_Transmit(
        //        &huart1,
        //        (uint8_t*)uart_msg,
        //        strlen(uart_msg),
        //        100
        //    );

        //    // liten delay så servo hinner
        //    vTaskDelay(pdMS_TO_TICKS(300));

        //    // SHOOT var 4e sekund
        //    shoot_timer++;

        //    if(shoot_timer >= 4) {

        //        shoot_timer = 0;

        //        char shoot_cmd[] = "SHOOT\n";

        //        HAL_UART_Transmit(
        //            &huart1,
        //            (uint8_t*)shoot_cmd,
        //            strlen(shoot_cmd),
        //            100
        //        );
        //    }
        //}

        // =========================
        // SEND THERMAL DATA
        // =========================

        telemetry_timer++;

        if(telemetry_timer >= 1) {

            telemetry_timer = 0;

            char thermal_data[512];

            thermal_data[0] = '\0';

            char temp_str[10];

            for(int i = 0; i < 64; i++) {

                sprintf(temp_str, "%d,", (int)pixels[i]);

                strcat(thermal_data, temp_str);
            }

            thermal_data[
                strlen(thermal_data) - 1
            ] = '\n';

            HAL_UART_Transmit(
                &huart2,
                (uint8_t*)thermal_data,
                strlen(thermal_data),
                100
            );
        }

        // =========================
        // DISPLAY
        // =========================

        draw_img(side_flag);

        vTaskDelay(pdMS_TO_TICKS(3000));
    }
}

void vCommandHandlerTask(void *params) {

    uint8_t recievedChar;

    char messageBuffer[64];

    int bufferIndex = 0;

    printf("Command Task lever och väntar på ESP32...\n");

    while (1) {

        if(xQueueReceive(uart_queue, &recievedChar, portMAX_DELAY) == pdTRUE) {

            if (recievedChar == '\r') {
                continue;
            }

            if(recievedChar == '\n') {
                messageBuffer[bufferIndex] = '\0';

                if (strcmp(messageBuffer, "MODE:AUTO") == 0) {
                  printf("hej\n");
                  auto_mode = 1;
                  thermal_mode = 0;
                }
                if (strcmp(messageBuffer, "MODE:THERMAL") == 0) {
                  thermal_mode = 1;
                  auto_mode = 0;
                }
                if (strcmp(messageBuffer, "MODE:MANUAL") == 0 || strcmp(messageBuffer, "STOP") == 0) {
                  auto_mode = 0;
                  thermal_mode = 0;
                }

                printf(
                    "RX CMD: %s\n",
                    messageBuffer
                );

                // vidare till maskincontroller
                HAL_UART_Transmit(
                    &huart1,
                    (uint8_t*)messageBuffer,
                    strlen(messageBuffer),
                    100
                );

                HAL_UART_Transmit(
                    &huart1,
                    (uint8_t*)"\n",
                    1,
                    100
                );

                bufferIndex = 0;
            }

            else {

                if(bufferIndex < 63) {

                    messageBuffer[bufferIndex++] =
                        recievedChar;
                }
            }
        }
    }
}

void HAL_UART_RxCpltCallback(
    UART_HandleTypeDef *huart
) {

    // DATA FRÅN ESP32
    if(huart->Instance == USART2) {

        BaseType_t xHigherPriorityTaskWoken =
            pdFALSE;

        xQueueSendFromISR(
            uart_queue,
            &rx_byte,
            &xHigherPriorityTaskWoken
        );

        // starta ny receive på USART2
        HAL_UART_Receive_IT(
            &huart2,
            &rx_byte,
            1
        );

        portYIELD_FROM_ISR(
            xHigherPriorityTaskWoken
        );
    }
}

/* USER CODE END 0 */

int main(void)
{

  /* USER CODE BEGIN 1 */
  float pixels[64];
  float sum_right;
  float sum_left;
  int side_flag = 0;

  /* USER CODE END 1 */

  /* MCU Configuration--------------------------------------------------------*/

  /* Reset of all peripherals, Initializes the Flash interface and the Systick. */
  HAL_Init();

  /* Configure the system clock */
  SystemClock_Config();

  /* Initialize all configured peripherals */
  MX_GPIO_Init();
  MX_USART1_UART_Init();
  MX_I2C1_Init();
  MX_SPI1_Init();
  MX_USART2_UART_Init();
  /* USER CODE BEGIN 2 */

  uint8_t raw[128];
  uint8_t sum = 0;

  ILI9341_Init();
  ILI9341_FillScreen(ILI9341_GREEN);
  draw_table();

  // Test för RTOS
  //// Start SystemView tracing
  //traceSTART();
  //// Create FreeRTOS tasks
  //xTaskCreate(task_a, "Task A", 128, NULL, 1, NULL);
  //xTaskCreate(task_b, "Task B", 128, NULL, 1, NULL);
  //// Start the FreeRTOS scheduler
  //vTaskStartScheduler();

  // setup för kommunikation

  traceSTART();

  uart_queue = xQueueCreate(64, sizeof(uint8_t));
  HAL_UART_Receive_IT(&huart2, &rx_byte, 1);

  xTaskCreate(vCommandHandlerTask, "CmdTask", 256, NULL, 2, NULL);

  xTaskCreate(vThermalDataTask, "ThermalTask", 512, NULL, 1, NULL);

  xTaskCreate(vAutoModeTask, "AutoTask", 512, NULL, 1, NULL);

  vTaskStartScheduler();

  /* USER CODE END 2 */

  /* Infinite loop */
  while (1)
  {

    /* USER CODE BEGIN 3 */

    //printf("\r\n========================\r\n");

    //for(int y = 0; y < 8; y++)
    //{
    //    for(int x = 0; x < 8; x++)
    //    {
    //        printf("%5.1f ", pixels[y * 8 + x]);
    //    }

    //    printf("\r\n");
    //}

  }
  /* USER CODE END 3 */
}

void SystemClock_Config(void)
{
  RCC_OscInitTypeDef RCC_OscInitStruct = {0};
  RCC_ClkInitTypeDef RCC_ClkInitStruct = {0};

  /** Configure the main internal regulator output voltage
  */
  if (HAL_PWREx_ControlVoltageScaling(PWR_REGULATOR_VOLTAGE_SCALE1) != HAL_OK)
  {
    Error_Handler();
  }

  /** Configure LSE Drive Capability
  */
  HAL_PWR_EnableBkUpAccess();
  __HAL_RCC_LSEDRIVE_CONFIG(RCC_LSEDRIVE_LOW);

  /** Initializes the RCC Oscillators according to the specified parameters
  * in the RCC_OscInitTypeDef structure.
  */
  RCC_OscInitStruct.OscillatorType = RCC_OSCILLATORTYPE_LSE|RCC_OSCILLATORTYPE_MSI;
  RCC_OscInitStruct.LSEState = RCC_LSE_ON;
  RCC_OscInitStruct.MSIState = RCC_MSI_ON;
  RCC_OscInitStruct.MSICalibrationValue = 0;
  RCC_OscInitStruct.MSIClockRange = RCC_MSIRANGE_6;
  RCC_OscInitStruct.PLL.PLLState = RCC_PLL_ON;
  RCC_OscInitStruct.PLL.PLLSource = RCC_PLLSOURCE_MSI;
  RCC_OscInitStruct.PLL.PLLM = 1;
  RCC_OscInitStruct.PLL.PLLN = 16;
  RCC_OscInitStruct.PLL.PLLP = RCC_PLLP_DIV7;
  RCC_OscInitStruct.PLL.PLLQ = RCC_PLLQ_DIV2;
  RCC_OscInitStruct.PLL.PLLR = RCC_PLLR_DIV2;
  if (HAL_RCC_OscConfig(&RCC_OscInitStruct) != HAL_OK)
  {
    Error_Handler();
  }

  /** Initializes the CPU, AHB and APB buses clocks
  */
  RCC_ClkInitStruct.ClockType = RCC_CLOCKTYPE_HCLK|RCC_CLOCKTYPE_SYSCLK
                              |RCC_CLOCKTYPE_PCLK1|RCC_CLOCKTYPE_PCLK2;
  RCC_ClkInitStruct.SYSCLKSource = RCC_SYSCLKSOURCE_PLLCLK;
  RCC_ClkInitStruct.AHBCLKDivider = RCC_SYSCLK_DIV1;
  RCC_ClkInitStruct.APB1CLKDivider = RCC_HCLK_DIV1;
  RCC_ClkInitStruct.APB2CLKDivider = RCC_HCLK_DIV1;

  if (HAL_RCC_ClockConfig(&RCC_ClkInitStruct, FLASH_LATENCY_1) != HAL_OK)
  {
    Error_Handler();
  }

  /** Enable MSI Auto calibration
  */
  HAL_RCCEx_EnableMSIPLLMode();
}

void HAL_TIM_PeriodElapsedCallback(TIM_HandleTypeDef *htim)
{
  if (htim->Instance == TIM2)
  {
    HAL_IncTick();
  }
}

void Error_Handler(void)
{
  __disable_irq();
  while (1)
  {
  }
}
